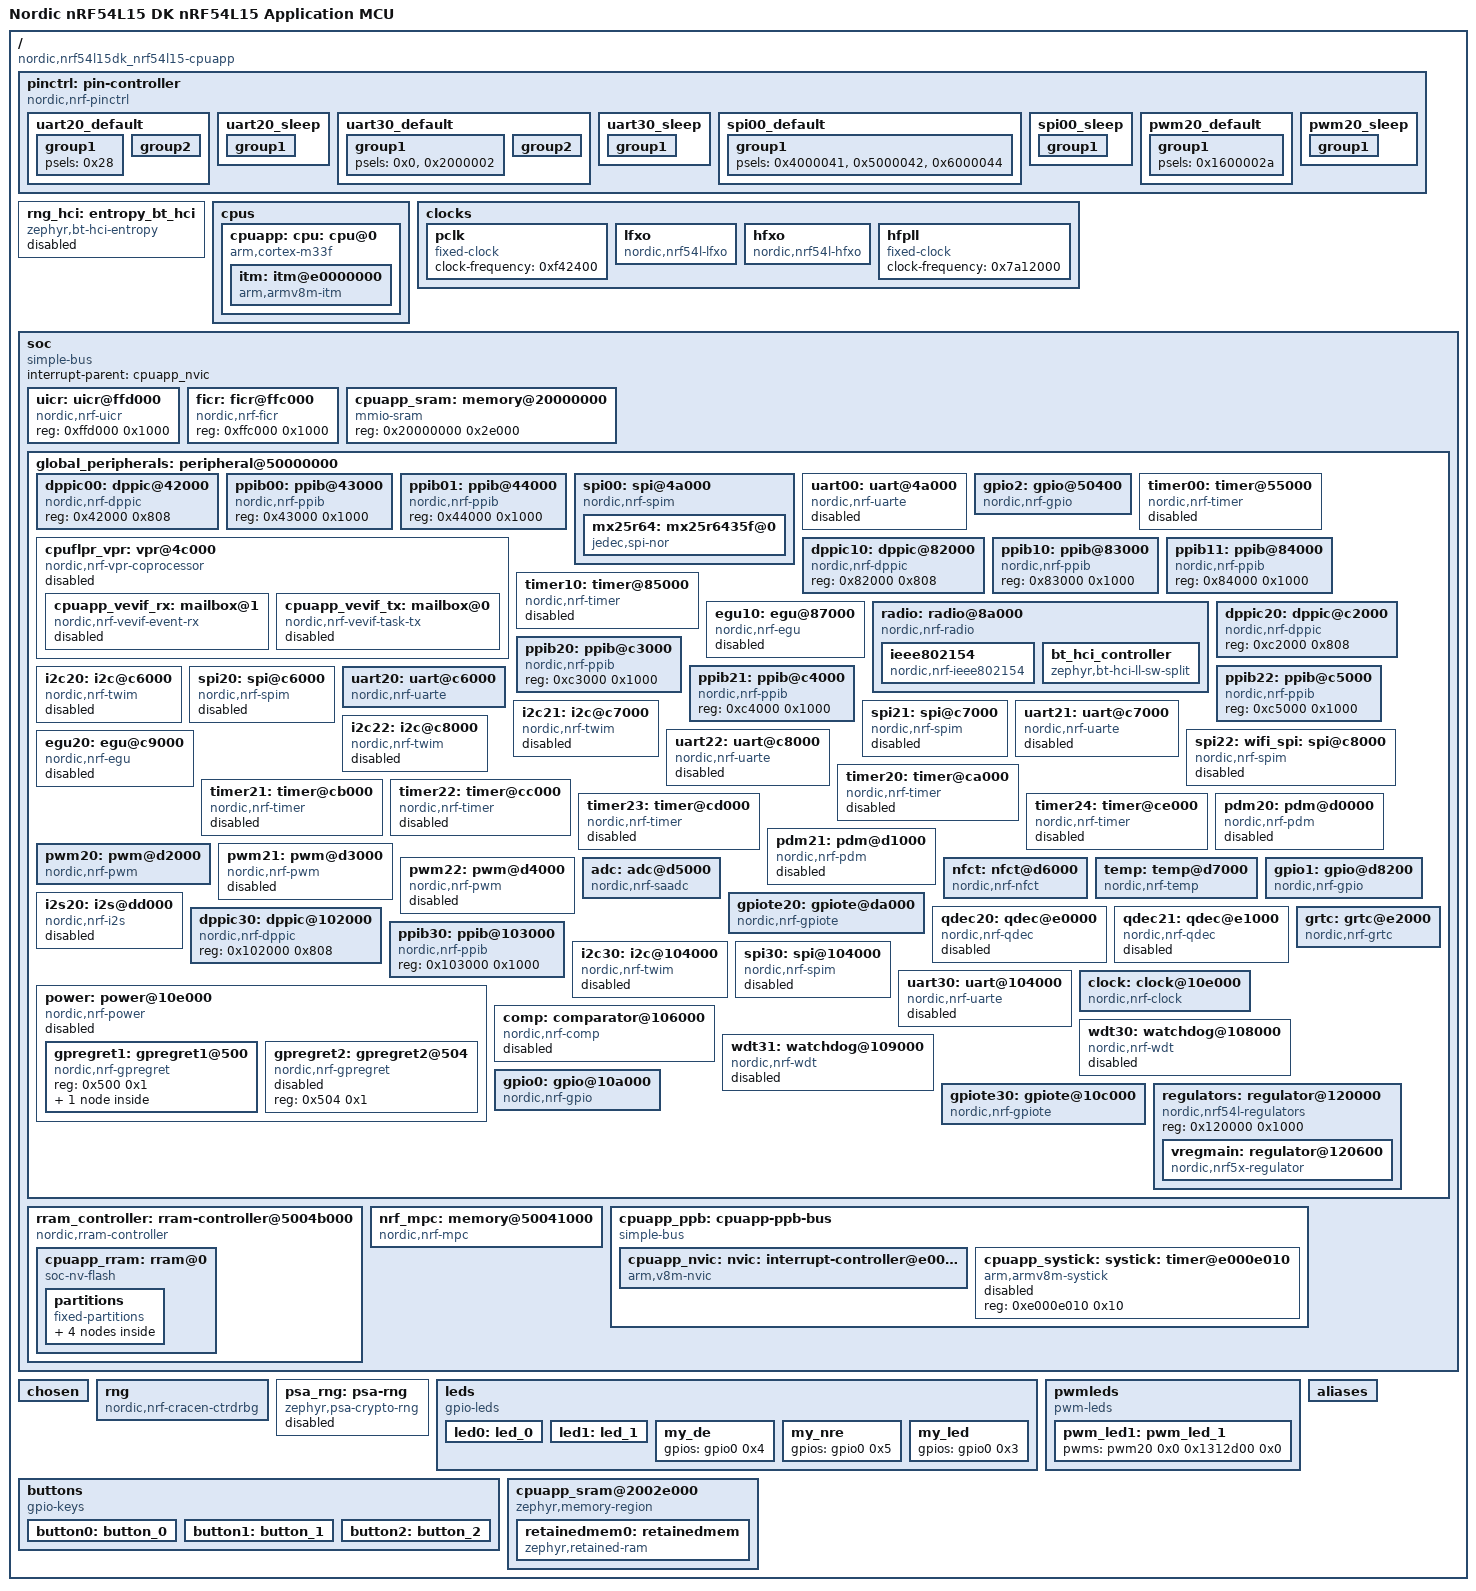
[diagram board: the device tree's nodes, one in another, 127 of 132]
/dts-v1/;

/* node '/' defined in zephyr\dts\vendor\nordic\nrf_common.dtsi:25 */
/ {
	#address-cells = < 0x1 >;                              /* in zephyr\dts\vendor\nordic\nrf54l_05_10_15.dtsi:19 */
	#size-cells = < 0x1 >;                                 /* in zephyr\dts\vendor\nordic\nrf54l_05_10_15.dtsi:20 */
	compatible = "nordic,nrf54l15dk_nrf54l15-cpuapp";      /* in zephyr\boards\nordic\nrf54l15dk\nrf54l15dk_nrf54l15_cpuapp.dts:13 */
	model = "Nordic nRF54L15 DK nRF54L15 Application MCU"; /* in zephyr\boards\nordic\nrf54l15dk\nrf54l15dk_nrf54l15_cpuapp.dts:14 */

	/* node '/pin-controller' defined in zephyr\dts\vendor\nordic\nrf_common.dtsi:26 */
	pinctrl: pin-controller {
		compatible = "nordic,nrf-pinctrl"; /* in zephyr\dts\vendor\nordic\nrf_common.dtsi:31 */

		/* node '/pin-controller/uart20_default' defined in zephyr\boards\nordic\nrf54l15dk\nrf54l15dk_nrf54l_05_10_15-pinctrl.dtsi:7 */
		uart20_default: uart20_default {
			phandle = < 0x8 >; /* in zephyr\boards\nordic\nrf54l15dk\nrf54l15dk_common.dtsi:92 */

			/* node '/pin-controller/uart20_default/group1' defined in zephyr\boards\nordic\nrf54l15dk\nrf54l15dk_nrf54l_05_10_15-pinctrl.dtsi:8 */
			group1 {
				psels = < 0x28 >; /* in zephyr\power_test\boards\nrf54l15dk_nrf54l15_cpuapp.overlay:9 */
			};

			/* node '/pin-controller/uart20_default/group2' defined in zephyr\boards\nordic\nrf54l15dk\nrf54l15dk_nrf54l_05_10_15-pinctrl.dtsi:13 */
			group2 {
				psels = < 0x1000029 >; /* in zephyr\power_test\boards\nrf54l15dk_nrf54l15_cpuapp.overlay:12 */
				bias-pull-up;          /* in zephyr\power_test\boards\nrf54l15dk_nrf54l15_cpuapp.overlay:13 */
			};
		};

		/* node '/pin-controller/uart20_sleep' defined in zephyr\boards\nordic\nrf54l15dk\nrf54l15dk_nrf54l_05_10_15-pinctrl.dtsi:20 */
		uart20_sleep: uart20_sleep {
			phandle = < 0x9 >; /* in zephyr\boards\nordic\nrf54l15dk\nrf54l15dk_common.dtsi:93 */

			/* node '/pin-controller/uart20_sleep/group1' defined in zephyr\boards\nordic\nrf54l15dk\nrf54l15dk_nrf54l_05_10_15-pinctrl.dtsi:21 */
			group1 {
				psels = < 0x28 >,
				        < 0x1000029 >; /* in zephyr\power_test\boards\nrf54l15dk_nrf54l15_cpuapp.overlay:19 */
				low-power-enable;      /* in zephyr\power_test\boards\nrf54l15dk_nrf54l15_cpuapp.overlay:21 */
			};
		};

		/* node '/pin-controller/uart30_default' defined in zephyr\boards\nordic\nrf54l15dk\nrf54l15dk_nrf54l_05_10_15-pinctrl.dtsi:30 */
		uart30_default: uart30_default {
			phandle = < 0xf >; /* in zephyr\boards\nordic\nrf54l15dk\nrf54l15dk_common.dtsi:99 */

			/* node '/pin-controller/uart30_default/group1' defined in zephyr\boards\nordic\nrf54l15dk\nrf54l15dk_nrf54l_05_10_15-pinctrl.dtsi:31 */
			group1 {
				psels = < 0x0 >,
				        < 0x2000002 >; /* in zephyr\power_test\boards\nrf54l15dk_nrf54l15_cpuapp.overlay:27 */
			};

			/* node '/pin-controller/uart30_default/group2' defined in zephyr\boards\nordic\nrf54l15dk\nrf54l15dk_nrf54l_05_10_15-pinctrl.dtsi:36 */
			group2 {
				psels = < 0x1000001 >,
				        < 0x3000003 >; /* in zephyr\power_test\boards\nrf54l15dk_nrf54l15_cpuapp.overlay:31 */
				bias-pull-up;          /* in zephyr\power_test\boards\nrf54l15dk_nrf54l15_cpuapp.overlay:33 */
			};
		};

		/* node '/pin-controller/uart30_sleep' defined in zephyr\boards\nordic\nrf54l15dk\nrf54l15dk_nrf54l_05_10_15-pinctrl.dtsi:43 */
		uart30_sleep: uart30_sleep {
			phandle = < 0x10 >; /* in zephyr\boards\nordic\nrf54l15dk\nrf54l15dk_common.dtsi:100 */

			/* node '/pin-controller/uart30_sleep/group1' defined in zephyr\boards\nordic\nrf54l15dk\nrf54l15dk_nrf54l_05_10_15-pinctrl.dtsi:44 */
			group1 {
				psels = < 0x0 >,
				        < 0x1000001 >,
				        < 0x2000002 >,
				        < 0x3000003 >; /* in zephyr\power_test\boards\nrf54l15dk_nrf54l15_cpuapp.overlay:39 */
				low-power-enable;      /* in zephyr\power_test\boards\nrf54l15dk_nrf54l15_cpuapp.overlay:43 */
			};
		};

		/* node '/pin-controller/spi00_default' defined in zephyr\boards\nordic\nrf54l15dk\nrf54l15dk_nrf54l_05_10_15-pinctrl.dtsi:53 */
		spi00_default: spi00_default {
			phandle = < 0x4 >; /* in zephyr\boards\nordic\nrf54l15dk\nrf54l_05_10_15_cpuapp_common.dtsi:117 */

			/* node '/pin-controller/spi00_default/group1' defined in zephyr\boards\nordic\nrf54l15dk\nrf54l15dk_nrf54l_05_10_15-pinctrl.dtsi:54 */
			group1 {
				psels = < 0x4000041 >,
				        < 0x5000042 >,
				        < 0x6000044 >; /* in zephyr\power_test\boards\nrf54l15dk_nrf54l15_cpuapp.overlay:49 */
			};
		};

		/* node '/pin-controller/spi00_sleep' defined in zephyr\boards\nordic\nrf54l15dk\nrf54l15dk_nrf54l_05_10_15-pinctrl.dtsi:61 */
		spi00_sleep: spi00_sleep {
			phandle = < 0x5 >; /* in zephyr\boards\nordic\nrf54l15dk\nrf54l_05_10_15_cpuapp_common.dtsi:118 */

			/* node '/pin-controller/spi00_sleep/group1' defined in zephyr\boards\nordic\nrf54l15dk\nrf54l15dk_nrf54l_05_10_15-pinctrl.dtsi:62 */
			group1 {
				psels = < 0x4000041 >,
				        < 0x5000042 >,
				        < 0x6000044 >; /* in zephyr\power_test\boards\nrf54l15dk_nrf54l15_cpuapp.overlay:57 */
				low-power-enable;      /* in zephyr\power_test\boards\nrf54l15dk_nrf54l15_cpuapp.overlay:60 */
			};
		};

		/* node '/pin-controller/pwm20_default' defined in zephyr\boards\nordic\nrf54l15dk\nrf54l15dk_nrf54l_05_10_15-pinctrl.dtsi:70 */
		pwm20_default: pwm20_default {
			phandle = < 0xa >; /* in zephyr\boards\nordic\nrf54l15dk\nrf54l15dk_common.dtsi:106 */

			/* node '/pin-controller/pwm20_default/group1' defined in zephyr\boards\nordic\nrf54l15dk\nrf54l15dk_nrf54l_05_10_15-pinctrl.dtsi:71 */
			group1 {
				psels = < 0x1600002a >; /* in zephyr\power_test\boards\nrf54l15dk_nrf54l15_cpuapp.overlay:66 */
			};
		};

		/* node '/pin-controller/pwm20_sleep' defined in zephyr\boards\nordic\nrf54l15dk\nrf54l15dk_nrf54l_05_10_15-pinctrl.dtsi:76 */
		pwm20_sleep: pwm20_sleep {
			phandle = < 0xb >; /* in zephyr\boards\nordic\nrf54l15dk\nrf54l15dk_common.dtsi:107 */

			/* node '/pin-controller/pwm20_sleep/group1' defined in zephyr\boards\nordic\nrf54l15dk\nrf54l15dk_nrf54l_05_10_15-pinctrl.dtsi:77 */
			group1 {
				psels = < 0x1600002a >; /* in zephyr\power_test\boards\nrf54l15dk_nrf54l15_cpuapp.overlay:72 */
				low-power-enable;       /* in zephyr\power_test\boards\nrf54l15dk_nrf54l15_cpuapp.overlay:73 */
			};
		};
	};

	/* node '/entropy_bt_hci' defined in zephyr\dts\vendor\nordic\nrf_common.dtsi:34 */
	rng_hci: entropy_bt_hci {
		compatible = "zephyr,bt-hci-entropy"; /* in zephyr\dts\vendor\nordic\nrf_common.dtsi:35 */
		status = "disabled";                  /* in zephyr\dts\vendor\nordic\nrf_common.dtsi:36 */
	};

	/* node '/cpus' defined in zephyr\dts\vendor\nordic\nrf54l_05_10_15.dtsi:22 */
	cpus {
		#address-cells = < 0x1 >; /* in zephyr\dts\vendor\nordic\nrf54l_05_10_15.dtsi:23 */
		#size-cells = < 0x0 >;    /* in zephyr\dts\vendor\nordic\nrf54l_05_10_15.dtsi:24 */

		/* node '/cpus/cpu@0' defined in zephyr\dts\vendor\nordic\nrf54l_05_10_15.dtsi:26 */
		cpuapp: cpu: cpu@0 {
			compatible = "arm,cortex-m33f"; /* in zephyr\dts\vendor\nordic\nrf54l_05_10_15.dtsi:27 */
			reg = < 0x0 >;                  /* in zephyr\dts\vendor\nordic\nrf54l_05_10_15.dtsi:28 */
			device_type = "cpu";            /* in zephyr\dts\vendor\nordic\nrf54l_05_10_15.dtsi:29 */
			clocks = < &hfpll >;            /* in zephyr\dts\vendor\nordic\nrf54l_05_10_15.dtsi:30 */
			#address-cells = < 0x1 >;       /* in zephyr\dts\vendor\nordic\nrf54l_05_10_15.dtsi:31 */
			#size-cells = < 0x1 >;          /* in zephyr\dts\vendor\nordic\nrf54l_05_10_15.dtsi:32 */

			/* node '/cpus/cpu@0/itm@e0000000' defined in zephyr\dts\vendor\nordic\nrf54l_05_10_15.dtsi:34 */
			itm: itm@e0000000 {
				compatible = "arm,armv8m-itm";     /* in zephyr\dts\vendor\nordic\nrf54l_05_10_15.dtsi:35 */
				reg = < 0xe0000000 0x1000 >;       /* in zephyr\dts\vendor\nordic\nrf54l_05_10_15.dtsi:36 */
				swo-ref-frequency = < 0x7a12000 >; /* in zephyr\dts\vendor\nordic\nrf54l_05_10_15.dtsi:37 */
			};
		};
	};

	/* node '/clocks' defined in zephyr\dts\vendor\nordic\nrf54l_05_10_15.dtsi:51 */
	clocks {

		/* node '/clocks/pclk' defined in zephyr\dts\vendor\nordic\nrf54l_05_10_15.dtsi:52 */
		pclk: pclk {
			compatible = "fixed-clock";     /* in zephyr\dts\vendor\nordic\nrf54l_05_10_15.dtsi:53 */
			#clock-cells = < 0x0 >;         /* in zephyr\dts\vendor\nordic\nrf54l_05_10_15.dtsi:54 */
			clock-frequency = < 0xf42400 >; /* in zephyr\dts\vendor\nordic\nrf54l_05_10_15.dtsi:55 */
			phandle = < 0xe >;              /* in zephyr\dts\vendor\nordic\nrf54l_05_10_15.dtsi:580 */
		};

		/* node '/clocks/lfxo' defined in zephyr\dts\vendor\nordic\nrf54l_05_10_15.dtsi:58 */
		lfxo: lfxo {
			compatible = "nordic,nrf54l-lfxo";        /* in zephyr\dts\vendor\nordic\nrf54l_05_10_15.dtsi:59 */
			#clock-cells = < 0x0 >;                   /* in zephyr\dts\vendor\nordic\nrf54l_05_10_15.dtsi:60 */
			clock-frequency = < 0x8000 >;             /* in zephyr\dts\vendor\nordic\nrf54l_05_10_15.dtsi:61 */
			load-capacitors = "internal";             /* in zephyr\boards\nordic\nrf54l15dk\nrf54l_05_10_15_cpuapp_common.dtsi:35 */
			load-capacitance-femtofarad = < 0x4268 >; /* in zephyr\boards\nordic\nrf54l15dk\nrf54l_05_10_15_cpuapp_common.dtsi:36 */
			phandle = < 0xd >;                        /* in zephyr\dts\vendor\nordic\nrf54l_05_10_15.dtsi:580 */
		};

		/* node '/clocks/hfxo' defined in zephyr\dts\vendor\nordic\nrf54l_05_10_15.dtsi:64 */
		hfxo: hfxo {
			compatible = "nordic,nrf54l-hfxo";        /* in zephyr\dts\vendor\nordic\nrf54l_05_10_15.dtsi:65 */
			#clock-cells = < 0x0 >;                   /* in zephyr\dts\vendor\nordic\nrf54l_05_10_15.dtsi:66 */
			clock-frequency = < 0x1e84800 >;          /* in zephyr\dts\vendor\nordic\nrf54l_05_10_15.dtsi:67 */
			startup-time-us = < 0x672 >;              /* in zephyr\dts\vendor\nordic\nrf54l_05_10_15.dtsi:68 */
			load-capacitors = "internal";             /* in zephyr\boards\nordic\nrf54l15dk\nrf54l_05_10_15_cpuapp_common.dtsi:40 */
			load-capacitance-femtofarad = < 0x3a98 >; /* in zephyr\boards\nordic\nrf54l15dk\nrf54l_05_10_15_cpuapp_common.dtsi:41 */
			phandle = < 0x6 >;                        /* in zephyr\dts\vendor\nordic\nrf54l_05_10_15.dtsi:229 */
		};

		/* node '/clocks/hfpll' defined in zephyr\dts\vendor\nordic\nrf54l_05_10_15.dtsi:71 */
		hfpll: hfpll {
			compatible = "fixed-clock";      /* in zephyr\dts\vendor\nordic\nrf54l_05_10_15.dtsi:72 */
			#clock-cells = < 0x0 >;          /* in zephyr\dts\vendor\nordic\nrf54l_05_10_15.dtsi:73 */
			clock-frequency = < 0x7a12000 >; /* in zephyr\dts\vendor\nordic\nrf54l_05_10_15.dtsi:74 */
			phandle = < 0x1 >;               /* in zephyr\dts\vendor\nordic\nrf54l_05_10_15.dtsi:30 */
		};
	};

	/* node '/soc' defined in zephyr\dts\vendor\nordic\nrf54l_05_10_15.dtsi:78 */
	soc {
		#address-cells = < 0x1 >;            /* in zephyr\dts\vendor\nordic\nrf54l_05_10_15.dtsi:79 */
		#size-cells = < 0x1 >;               /* in zephyr\dts\vendor\nordic\nrf54l_05_10_15.dtsi:80 */
		compatible = "simple-bus";           /* in zephyr\dts\arm\nordic\nrf54l_05_10_15_cpuapp.dtsi:25 */
		interrupt-parent = < &cpuapp_nvic >; /* in zephyr\dts\arm\nordic\nrf54l_05_10_15_cpuapp.dtsi:26 */
		ranges;                              /* in zephyr\dts\arm\nordic\nrf54l_05_10_15_cpuapp.dtsi:27 */

		/* node '/soc/uicr@ffd000' defined in zephyr\dts\vendor\nordic\nrf54l_05_10_15.dtsi:86 */
		uicr: uicr@ffd000 {
			compatible = "nordic,nrf-uicr"; /* in zephyr\dts\vendor\nordic\nrf54l_05_10_15.dtsi:87 */
			reg = < 0xffd000 0x1000 >;      /* in zephyr\dts\vendor\nordic\nrf54l_05_10_15.dtsi:88 */
		};

		/* node '/soc/ficr@ffc000' defined in zephyr\dts\vendor\nordic\nrf54l_05_10_15.dtsi:92 */
		ficr: ficr@ffc000 {
			compatible = "nordic,nrf-ficr"; /* in zephyr\dts\vendor\nordic\nrf54l_05_10_15.dtsi:93 */
			reg = < 0xffc000 0x1000 >;      /* in zephyr\dts\vendor\nordic\nrf54l_05_10_15.dtsi:94 */
			#nordic,ficr-cells = < 0x1 >;   /* in zephyr\dts\vendor\nordic\nrf54l_05_10_15.dtsi:95 */
		};

		/* node '/soc/memory@20000000' defined in zephyr\dts\vendor\nordic\nrf54l_05_10_15.dtsi:98 */
		cpuapp_sram: memory@20000000 {
			compatible = "mmio-sram";            /* in zephyr\dts\vendor\nordic\nrf54l_05_10_15.dtsi:99 */
			#address-cells = < 0x1 >;            /* in zephyr\dts\vendor\nordic\nrf54l_05_10_15.dtsi:100 */
			#size-cells = < 0x1 >;               /* in zephyr\dts\vendor\nordic\nrf54l_05_10_15.dtsi:101 */
			status = "okay";                     /* in zephyr\boards\nordic\nrf54l15dk\nrf54l_05_10_15_cpuapp_common.dtsi:31 */
			reg = < 0x20000000 0x2e000 >;        /* in zephyr\power_test\boards\nrf54l15dk_nrf54l15_cpuapp.overlay:107 */
			ranges = < 0x0 0x20000000 0x2e000 >; /* in zephyr\power_test\boards\nrf54l15dk_nrf54l15_cpuapp.overlay:108 */
		};

		/* node '/soc/peripheral@50000000' defined in zephyr\dts\vendor\nordic\nrf54l_05_10_15.dtsi:111 */
		global_peripherals: peripheral@50000000 {
			#address-cells = < 0x1 >;               /* in zephyr\dts\vendor\nordic\nrf54l_05_10_15.dtsi:112 */
			#size-cells = < 0x1 >;                  /* in zephyr\dts\vendor\nordic\nrf54l_05_10_15.dtsi:113 */
			ranges = < 0x0 0x50000000 0x10000000 >; /* in zephyr\dts\vendor\nordic\nrf54l_05_10_15.dtsi:114 */

			/* node '/soc/peripheral@50000000/dppic@42000' defined in zephyr\dts\vendor\nordic\nrf54l_05_10_15.dtsi:117 */
			dppic00: dppic@42000 {
				compatible = "nordic,nrf-dppic"; /* in zephyr\dts\vendor\nordic\nrf54l_05_10_15.dtsi:118 */
				reg = < 0x42000 0x808 >;         /* in zephyr\dts\vendor\nordic\nrf54l_05_10_15.dtsi:119 */
				status = "okay";                 /* in zephyr\dts\arm\nordic\nrf54l_05_10_15_cpuapp.dtsi:97 */
			};

			/* node '/soc/peripheral@50000000/ppib@43000' defined in zephyr\dts\vendor\nordic\nrf54l_05_10_15.dtsi:123 */
			ppib00: ppib@43000 {
				compatible = "nordic,nrf-ppib"; /* in zephyr\dts\vendor\nordic\nrf54l_05_10_15.dtsi:124 */
				reg = < 0x43000 0x1000 >;       /* in zephyr\dts\vendor\nordic\nrf54l_05_10_15.dtsi:125 */
				status = "okay";                /* in zephyr\dts\arm\nordic\nrf54l_05_10_15_cpuapp.dtsi:113 */
			};

			/* node '/soc/peripheral@50000000/ppib@44000' defined in zephyr\dts\vendor\nordic\nrf54l_05_10_15.dtsi:129 */
			ppib01: ppib@44000 {
				compatible = "nordic,nrf-ppib"; /* in zephyr\dts\vendor\nordic\nrf54l_05_10_15.dtsi:130 */
				reg = < 0x44000 0x1000 >;       /* in zephyr\dts\vendor\nordic\nrf54l_05_10_15.dtsi:131 */
				status = "okay";                /* in zephyr\dts\arm\nordic\nrf54l_05_10_15_cpuapp.dtsi:117 */
			};

			/* node '/soc/peripheral@50000000/spi@4a000' defined in zephyr\dts\vendor\nordic\nrf54l_05_10_15.dtsi:135 */
			spi00: spi@4a000 {
				compatible = "nordic,nrf-spim"; /* in zephyr\dts\vendor\nordic\nrf54l_05_10_15.dtsi:142 */
				#address-cells = < 0x1 >;       /* in zephyr\dts\vendor\nordic\nrf54l_05_10_15.dtsi:143 */
				#size-cells = < 0x0 >;          /* in zephyr\dts\vendor\nordic\nrf54l_05_10_15.dtsi:144 */
				reg = < 0x4a000 0x1000 >;       /* in zephyr\dts\vendor\nordic\nrf54l_05_10_15.dtsi:145 */
				interrupts = < 0x4a 0x1 >;      /* in zephyr\dts\vendor\nordic\nrf54l_05_10_15.dtsi:146 */
				max-frequency = < 0x1e84800 >;  /* in zephyr\dts\vendor\nordic\nrf54l_05_10_15.dtsi:147 */
				easydma-maxcnt-bits = < 0x10 >; /* in zephyr\dts\vendor\nordic\nrf54l_05_10_15.dtsi:148 */
				rx-delay-supported;             /* in zephyr\dts\vendor\nordic\nrf54l_05_10_15.dtsi:149 */
				rx-delay = < 0x1 >;             /* in zephyr\dts\vendor\nordic\nrf54l_05_10_15.dtsi:150 */
				status = "okay";                /* in zephyr\boards\nordic\nrf54l15dk\nrf54l_05_10_15_cpuapp_common.dtsi:115 */
				cs-gpios = < &gpio2 0x5 0x1 >;  /* in zephyr\boards\nordic\nrf54l15dk\nrf54l_05_10_15_cpuapp_common.dtsi:116 */
				pinctrl-0 = < &spi00_default >; /* in zephyr\boards\nordic\nrf54l15dk\nrf54l_05_10_15_cpuapp_common.dtsi:117 */
				pinctrl-1 = < &spi00_sleep >;   /* in zephyr\boards\nordic\nrf54l15dk\nrf54l_05_10_15_cpuapp_common.dtsi:118 */
				pinctrl-names = "default",
				                "sleep";        /* in zephyr\boards\nordic\nrf54l15dk\nrf54l_05_10_15_cpuapp_common.dtsi:119 */

				/* node '/soc/peripheral@50000000/spi@4a000/mx25r6435f@0' defined in zephyr\boards\nordic\nrf54l15dk\nrf54l_05_10_15_cpuapp_common.dtsi:121 */
				mx25r64: mx25r6435f@0 {
					compatible = "jedec,spi-nor";                                                                 /* in zephyr\boards\nordic\nrf54l15dk\nrf54l_05_10_15_cpuapp_common.dtsi:122 */
					status = "okay";                                                                              /* in zephyr\boards\nordic\nrf54l15dk\nrf54l_05_10_15_cpuapp_common.dtsi:123 */
					reg = < 0x0 >;                                                                                /* in zephyr\boards\nordic\nrf54l15dk\nrf54l_05_10_15_cpuapp_common.dtsi:124 */
					spi-max-frequency = < 0x7a1200 >;                                                             /* in zephyr\boards\nordic\nrf54l15dk\nrf54l_05_10_15_cpuapp_common.dtsi:125 */
					jedec-id = [ C2 28 17 ];                                                                      /* in zephyr\boards\nordic\nrf54l15dk\nrf54l_05_10_15_cpuapp_common.dtsi:126 */
					sfdp-bfp = [ E5 20 F1 FF FF FF FF 03 44 EB 08 6B 08 3B 04 BB EE FF FF FF FF FF 00 FF FF FF 00
					             FF 0C 20 0F 52 10 D8 00 FF 23 72 F5 00 82 ED 04 CC 44 83 48 44 30 B0 30 B0 F7 C4
					             D5 5C 00 BE 29 FF F0 D0 FF FF ];                                                 /* in zephyr\boards\nordic\nrf54l15dk\nrf54l_05_10_15_cpuapp_common.dtsi:127 */
					size = < 0x4000000 >;                                                                         /* in zephyr\boards\nordic\nrf54l15dk\nrf54l_05_10_15_cpuapp_common.dtsi:131 */
					has-dpd;                                                                                      /* in zephyr\boards\nordic\nrf54l15dk\nrf54l_05_10_15_cpuapp_common.dtsi:132 */
					t-enter-dpd = < 0x2710 >;                                                                     /* in zephyr\boards\nordic\nrf54l15dk\nrf54l_05_10_15_cpuapp_common.dtsi:133 */
					t-exit-dpd = < 0x88b8 >;                                                                      /* in zephyr\boards\nordic\nrf54l15dk\nrf54l_05_10_15_cpuapp_common.dtsi:134 */
					reset-gpios = < &gpio2 0x0 0x1 >;                                                             /* in zephyr\boards\nordic\nrf54l15dk\nrf54l_05_10_15_cpuapp_common.dtsi:135 */
				};
			};

			/* node '/soc/peripheral@50000000/uart@4a000' defined in zephyr\dts\vendor\nordic\nrf54l_05_10_15.dtsi:154 */
			uart00: uart@4a000 {
				compatible = "nordic,nrf-uarte"; /* in zephyr\dts\vendor\nordic\nrf54l_05_10_15.dtsi:155 */
				reg = < 0x4a000 0x1000 >;        /* in zephyr\dts\vendor\nordic\nrf54l_05_10_15.dtsi:156 */
				interrupts = < 0x4a 0x1 >;       /* in zephyr\dts\vendor\nordic\nrf54l_05_10_15.dtsi:157 */
				clocks = < &hfpll >;             /* in zephyr\dts\vendor\nordic\nrf54l_05_10_15.dtsi:158 */
				status = "disabled";             /* in zephyr\dts\vendor\nordic\nrf54l_05_10_15.dtsi:159 */
				endtx-stoptx-supported;          /* in zephyr\dts\vendor\nordic\nrf54l_05_10_15.dtsi:160 */
				frame-timeout-supported;         /* in zephyr\dts\vendor\nordic\nrf54l_05_10_15.dtsi:161 */
			};

			/* node '/soc/peripheral@50000000/vpr@4c000' defined in zephyr\dts\vendor\nordic\nrf54l_05_10_15.dtsi:164 */
			cpuflpr_vpr: vpr@4c000 {
				compatible = "nordic,nrf-vpr-coprocessor"; /* in zephyr\dts\vendor\nordic\nrf54l_05_10_15.dtsi:165 */
				reg = < 0x4c000 0x1000 >;                  /* in zephyr\dts\vendor\nordic\nrf54l_05_10_15.dtsi:166 */
				ranges = < 0x0 0x4c000 0x1000 >;           /* in zephyr\dts\vendor\nordic\nrf54l_05_10_15.dtsi:167 */
				#address-cells = < 0x1 >;                  /* in zephyr\dts\vendor\nordic\nrf54l_05_10_15.dtsi:168 */
				#size-cells = < 0x1 >;                     /* in zephyr\dts\vendor\nordic\nrf54l_05_10_15.dtsi:169 */
				status = "disabled";                       /* in zephyr\dts\vendor\nordic\nrf54l_05_10_15.dtsi:170 */
				enable-secure;                             /* in zephyr\dts\vendor\nordic\nrf54l_05_10_15.dtsi:171 */

				/* node '/soc/peripheral@50000000/vpr@4c000/mailbox@1' defined in zephyr\dts\arm\nordic\nrf54l_05_10_15_cpuapp.dtsi:46 */
				cpuapp_vevif_rx: mailbox@1 {
					compatible = "nordic,nrf-vevif-event-rx"; /* in zephyr\dts\arm\nordic\nrf54l_05_10_15_cpuapp.dtsi:47 */
					reg = < 0x1 0x1000 >;                     /* in zephyr\dts\arm\nordic\nrf54l_05_10_15_cpuapp.dtsi:48 */
					status = "disabled";                      /* in zephyr\dts\arm\nordic\nrf54l_05_10_15_cpuapp.dtsi:49 */
					interrupts = < 0x4c 0x1 >;                /* in zephyr\dts\arm\nordic\nrf54l_05_10_15_cpuapp.dtsi:50 */
					#mbox-cells = < 0x1 >;                    /* in zephyr\dts\arm\nordic\nrf54l_05_10_15_cpuapp.dtsi:51 */
					nordic,events = < 0x1 >;                  /* in zephyr\dts\arm\nordic\nrf54l_05_10_15_cpuapp.dtsi:52 */
					nordic,events-mask = < 0x100000 >;        /* in zephyr\dts\arm\nordic\nrf54l_05_10_15_cpuapp.dtsi:53 */
				};

				/* node '/soc/peripheral@50000000/vpr@4c000/mailbox@0' defined in zephyr\dts\arm\nordic\nrf54l_05_10_15_cpuapp.dtsi:56 */
				cpuapp_vevif_tx: mailbox@0 {
					compatible = "nordic,nrf-vevif-task-tx"; /* in zephyr\dts\arm\nordic\nrf54l_05_10_15_cpuapp.dtsi:57 */
					reg = < 0x0 0x1000 >;                    /* in zephyr\dts\arm\nordic\nrf54l_05_10_15_cpuapp.dtsi:58 */
					#mbox-cells = < 0x1 >;                   /* in zephyr\dts\arm\nordic\nrf54l_05_10_15_cpuapp.dtsi:59 */
					nordic,tasks = < 0x7 >;                  /* in zephyr\dts\arm\nordic\nrf54l_05_10_15_cpuapp.dtsi:60 */
					nordic,tasks-mask = < 0x7f0000 >;        /* in zephyr\dts\arm\nordic\nrf54l_05_10_15_cpuapp.dtsi:61 */
					status = "disabled";                     /* in zephyr\dts\arm\nordic\nrf54l_05_10_15_cpuapp.dtsi:62 */
				};
			};

			/* node '/soc/peripheral@50000000/gpio@50400' defined in zephyr\dts\vendor\nordic\nrf54l_05_10_15.dtsi:183 */
			gpio2: gpio@50400 {
				compatible = "nordic,nrf-gpio"; /* in zephyr\dts\vendor\nordic\nrf54l_05_10_15.dtsi:184 */
				gpio-controller;                /* in zephyr\dts\vendor\nordic\nrf54l_05_10_15.dtsi:185 */
				reg = < 0x50400 0x300 >;        /* in zephyr\dts\vendor\nordic\nrf54l_05_10_15.dtsi:186 */
				#gpio-cells = < 0x2 >;          /* in zephyr\dts\vendor\nordic\nrf54l_05_10_15.dtsi:187 */
				ngpios = < 0xb >;               /* in zephyr\dts\vendor\nordic\nrf54l_05_10_15.dtsi:188 */
				port = < 0x2 >;                 /* in zephyr\dts\vendor\nordic\nrf54l_05_10_15.dtsi:190 */
				status = "okay";                /* in zephyr\boards\nordic\nrf54l15dk\nrf54l_05_10_15_cpuapp_common.dtsi:77 */
				phandle = < 0x3 >;              /* in zephyr\boards\nordic\nrf54l15dk\nrf54l_05_10_15_cpuapp_common.dtsi:116 */
			};

			/* node '/soc/peripheral@50000000/timer@55000' defined in zephyr\dts\vendor\nordic\nrf54l_05_10_15.dtsi:193 */
			timer00: timer@55000 {
				compatible = "nordic,nrf-timer"; /* in zephyr\dts\vendor\nordic\nrf54l_05_10_15.dtsi:194 */
				status = "disabled";             /* in zephyr\dts\vendor\nordic\nrf54l_05_10_15.dtsi:195 */
				reg = < 0x55000 0x1000 >;        /* in zephyr\dts\vendor\nordic\nrf54l_05_10_15.dtsi:196 */
				cc-num = < 0x6 >;                /* in zephyr\dts\vendor\nordic\nrf54l_05_10_15.dtsi:197 */
				max-bit-width = < 0x20 >;        /* in zephyr\dts\vendor\nordic\nrf54l_05_10_15.dtsi:198 */
				interrupts = < 0x55 0x1 >;       /* in zephyr\dts\vendor\nordic\nrf54l_05_10_15.dtsi:199 */
				clocks = < &hfpll >;             /* in zephyr\dts\vendor\nordic\nrf54l_05_10_15.dtsi:200 */
				prescaler = < 0x0 >;             /* in zephyr\dts\vendor\nordic\nrf54l_05_10_15.dtsi:201 */
			};

			/* node '/soc/peripheral@50000000/dppic@82000' defined in zephyr\dts\vendor\nordic\nrf54l_05_10_15.dtsi:204 */
			dppic10: dppic@82000 {
				compatible = "nordic,nrf-dppic"; /* in zephyr\dts\vendor\nordic\nrf54l_05_10_15.dtsi:205 */
				reg = < 0x82000 0x808 >;         /* in zephyr\dts\vendor\nordic\nrf54l_05_10_15.dtsi:206 */
				status = "okay";                 /* in zephyr\dts\arm\nordic\nrf54l_05_10_15_cpuapp.dtsi:101 */
			};

			/* node '/soc/peripheral@50000000/ppib@83000' defined in zephyr\dts\vendor\nordic\nrf54l_05_10_15.dtsi:210 */
			ppib10: ppib@83000 {
				compatible = "nordic,nrf-ppib"; /* in zephyr\dts\vendor\nordic\nrf54l_05_10_15.dtsi:211 */
				reg = < 0x83000 0x1000 >;       /* in zephyr\dts\vendor\nordic\nrf54l_05_10_15.dtsi:212 */
				status = "okay";                /* in zephyr\dts\arm\nordic\nrf54l_05_10_15_cpuapp.dtsi:121 */
			};

			/* node '/soc/peripheral@50000000/ppib@84000' defined in zephyr\dts\vendor\nordic\nrf54l_05_10_15.dtsi:216 */
			ppib11: ppib@84000 {
				compatible = "nordic,nrf-ppib"; /* in zephyr\dts\vendor\nordic\nrf54l_05_10_15.dtsi:217 */
				reg = < 0x84000 0x1000 >;       /* in zephyr\dts\vendor\nordic\nrf54l_05_10_15.dtsi:218 */
				status = "okay";                /* in zephyr\dts\arm\nordic\nrf54l_05_10_15_cpuapp.dtsi:125 */
			};

			/* node '/soc/peripheral@50000000/timer@85000' defined in zephyr\dts\vendor\nordic\nrf54l_05_10_15.dtsi:222 */
			timer10: timer@85000 {
				compatible = "nordic,nrf-timer"; /* in zephyr\dts\vendor\nordic\nrf54l_05_10_15.dtsi:223 */
				status = "disabled";             /* in zephyr\dts\vendor\nordic\nrf54l_05_10_15.dtsi:224 */
				reg = < 0x85000 0x1000 >;        /* in zephyr\dts\vendor\nordic\nrf54l_05_10_15.dtsi:225 */
				cc-num = < 0x8 >;                /* in zephyr\dts\vendor\nordic\nrf54l_05_10_15.dtsi:226 */
				max-bit-width = < 0x20 >;        /* in zephyr\dts\vendor\nordic\nrf54l_05_10_15.dtsi:227 */
				interrupts = < 0x85 0x1 >;       /* in zephyr\dts\vendor\nordic\nrf54l_05_10_15.dtsi:228 */
				clocks = < &hfxo >;              /* in zephyr\dts\vendor\nordic\nrf54l_05_10_15.dtsi:229 */
				prescaler = < 0x0 >;             /* in zephyr\dts\vendor\nordic\nrf54l_05_10_15.dtsi:230 */
			};

			/* node '/soc/peripheral@50000000/egu@87000' defined in zephyr\dts\vendor\nordic\nrf54l_05_10_15.dtsi:233 */
			egu10: egu@87000 {
				compatible = "nordic,nrf-egu"; /* in zephyr\dts\vendor\nordic\nrf54l_05_10_15.dtsi:234 */
				reg = < 0x87000 0x1000 >;      /* in zephyr\dts\vendor\nordic\nrf54l_05_10_15.dtsi:235 */
				interrupts = < 0x87 0x1 >;     /* in zephyr\dts\vendor\nordic\nrf54l_05_10_15.dtsi:236 */
				status = "disabled";           /* in zephyr\dts\vendor\nordic\nrf54l_05_10_15.dtsi:237 */
			};

			/* node '/soc/peripheral@50000000/radio@8a000' defined in zephyr\dts\vendor\nordic\nrf54l_05_10_15.dtsi:240 */
			radio: radio@8a000 {
				compatible = "nordic,nrf-radio"; /* in zephyr\dts\vendor\nordic\nrf54l_05_10_15.dtsi:241 */
				reg = < 0x8a000 0x1000 >;        /* in zephyr\dts\vendor\nordic\nrf54l_05_10_15.dtsi:242 */
				interrupts = < 0x8a 0x1 >;       /* in zephyr\dts\vendor\nordic\nrf54l_05_10_15.dtsi:243 */
				dfe-supported;                   /* in zephyr\dts\vendor\nordic\nrf54l_05_10_15.dtsi:245 */
				ieee802154-supported;            /* in zephyr\dts\vendor\nordic\nrf54l_05_10_15.dtsi:246 */
				ble-2mbps-supported;             /* in zephyr\dts\vendor\nordic\nrf54l_05_10_15.dtsi:247 */
				ble-coded-phy-supported;         /* in zephyr\dts\vendor\nordic\nrf54l_05_10_15.dtsi:248 */
				cs-supported;                    /* in zephyr\dts\vendor\nordic\nrf54l_05_10_15.dtsi:249 */
				status = "okay";                 /* in zephyr\boards\nordic\nrf54l15dk\nrf54l_05_10_15_cpuapp_common.dtsi:89 */

				/* node '/soc/peripheral@50000000/radio@8a000/ieee802154' defined in zephyr\dts\vendor\nordic\nrf54l_05_10_15.dtsi:251 */
				ieee802154: ieee802154 {
					compatible = "nordic,nrf-ieee802154"; /* in zephyr\dts\vendor\nordic\nrf54l_05_10_15.dtsi:252 */
					status = "okay";                      /* in zephyr\power_test\boards\nrf54l15dk_nrf54l15_cpuapp.overlay:160 */
				};

				/* node '/soc/peripheral@50000000/radio@8a000/bt_hci_controller' defined in zephyr\dts\vendor\nordic\nrf54l_05_10_15.dtsi:259 */
				bt_hci_controller: bt_hci_controller {
					compatible = "zephyr,bt-hci-ll-sw-split"; /* in zephyr\dts\vendor\nordic\nrf54l_05_10_15.dtsi:260 */
					status = "okay";                          /* in zephyr\dts\arm\nordic\nrf54l_05_10_15_cpuapp.dtsi:42 */
				};
			};

			/* node '/soc/peripheral@50000000/dppic@c2000' defined in zephyr\dts\vendor\nordic\nrf54l_05_10_15.dtsi:265 */
			dppic20: dppic@c2000 {
				compatible = "nordic,nrf-dppic"; /* in zephyr\dts\vendor\nordic\nrf54l_05_10_15.dtsi:266 */
				reg = < 0xc2000 0x808 >;         /* in zephyr\dts\vendor\nordic\nrf54l_05_10_15.dtsi:267 */
				status = "okay";                 /* in zephyr\dts\arm\nordic\nrf54l_05_10_15_cpuapp.dtsi:105 */
			};

			/* node '/soc/peripheral@50000000/ppib@c3000' defined in zephyr\dts\vendor\nordic\nrf54l_05_10_15.dtsi:271 */
			ppib20: ppib@c3000 {
				compatible = "nordic,nrf-ppib"; /* in zephyr\dts\vendor\nordic\nrf54l_05_10_15.dtsi:272 */
				reg = < 0xc3000 0x1000 >;       /* in zephyr\dts\vendor\nordic\nrf54l_05_10_15.dtsi:273 */
				status = "okay";                /* in zephyr\dts\arm\nordic\nrf54l_05_10_15_cpuapp.dtsi:129 */
			};

			/* node '/soc/peripheral@50000000/ppib@c4000' defined in zephyr\dts\vendor\nordic\nrf54l_05_10_15.dtsi:277 */
			ppib21: ppib@c4000 {
				compatible = "nordic,nrf-ppib"; /* in zephyr\dts\vendor\nordic\nrf54l_05_10_15.dtsi:278 */
				reg = < 0xc4000 0x1000 >;       /* in zephyr\dts\vendor\nordic\nrf54l_05_10_15.dtsi:279 */
				status = "okay";                /* in zephyr\dts\arm\nordic\nrf54l_05_10_15_cpuapp.dtsi:133 */
			};

			/* node '/soc/peripheral@50000000/ppib@c5000' defined in zephyr\dts\vendor\nordic\nrf54l_05_10_15.dtsi:283 */
			ppib22: ppib@c5000 {
				compatible = "nordic,nrf-ppib"; /* in zephyr\dts\vendor\nordic\nrf54l_05_10_15.dtsi:284 */
				reg = < 0xc5000 0x1000 >;       /* in zephyr\dts\vendor\nordic\nrf54l_05_10_15.dtsi:285 */
				status = "okay";                /* in zephyr\dts\arm\nordic\nrf54l_05_10_15_cpuapp.dtsi:137 */
			};

			/* node '/soc/peripheral@50000000/i2c@c6000' defined in zephyr\dts\vendor\nordic\nrf54l_05_10_15.dtsi:289 */
			i2c20: i2c@c6000 {
				compatible = "nordic,nrf-twim"; /* in zephyr\dts\vendor\nordic\nrf54l_05_10_15.dtsi:290 */
				#address-cells = < 0x1 >;       /* in zephyr\dts\vendor\nordic\nrf54l_05_10_15.dtsi:291 */
				#size-cells = < 0x0 >;          /* in zephyr\dts\vendor\nordic\nrf54l_05_10_15.dtsi:292 */
				reg = < 0xc6000 0x1000 >;       /* in zephyr\dts\vendor\nordic\nrf54l_05_10_15.dtsi:293 */
				interrupts = < 0xc6 0x1 >;      /* in zephyr\dts\vendor\nordic\nrf54l_05_10_15.dtsi:294 */
				easydma-maxcnt-bits = < 0x10 >; /* in zephyr\dts\vendor\nordic\nrf54l_05_10_15.dtsi:295 */
				status = "disabled";            /* in zephyr\dts\vendor\nordic\nrf54l_05_10_15.dtsi:296 */
				zephyr,pm-device-runtime-auto;  /* in zephyr\dts\vendor\nordic\nrf54l_05_10_15.dtsi:297 */
			};

			/* node '/soc/peripheral@50000000/spi@c6000' defined in zephyr\dts\vendor\nordic\nrf54l_05_10_15.dtsi:300 */
			spi20: spi@c6000 {
				compatible = "nordic,nrf-spim"; /* in zephyr\dts\vendor\nordic\nrf54l_05_10_15.dtsi:307 */
				#address-cells = < 0x1 >;       /* in zephyr\dts\vendor\nordic\nrf54l_05_10_15.dtsi:308 */
				#size-cells = < 0x0 >;          /* in zephyr\dts\vendor\nordic\nrf54l_05_10_15.dtsi:309 */
				reg = < 0xc6000 0x1000 >;       /* in zephyr\dts\vendor\nordic\nrf54l_05_10_15.dtsi:310 */
				interrupts = < 0xc6 0x1 >;      /* in zephyr\dts\vendor\nordic\nrf54l_05_10_15.dtsi:311 */
				max-frequency = < 0x7a1200 >;   /* in zephyr\dts\vendor\nordic\nrf54l_05_10_15.dtsi:312 */
				easydma-maxcnt-bits = < 0x10 >; /* in zephyr\dts\vendor\nordic\nrf54l_05_10_15.dtsi:313 */
				rx-delay-supported;             /* in zephyr\dts\vendor\nordic\nrf54l_05_10_15.dtsi:314 */
				rx-delay = < 0x1 >;             /* in zephyr\dts\vendor\nordic\nrf54l_05_10_15.dtsi:315 */
				status = "disabled";            /* in zephyr\dts\vendor\nordic\nrf54l_05_10_15.dtsi:316 */
				default-gpio-port = < &gpio1 >; /* in zephyr\dts\vendor\nordic\nrf54l_05_10_15.dtsi:317 */
				cross-domain-pins-supported;    /* in zephyr\dts\vendor\nordic\nrf54l_05_10_15.dtsi:318 */
			};

			/* node '/soc/peripheral@50000000/uart@c6000' defined in zephyr\dts\vendor\nordic\nrf54l_05_10_15.dtsi:321 */
			uart20: uart@c6000 {
				compatible = "nordic,nrf-uarte"; /* in zephyr\dts\vendor\nordic\nrf54l_05_10_15.dtsi:322 */
				reg = < 0xc6000 0x1000 >;        /* in zephyr\dts\vendor\nordic\nrf54l_05_10_15.dtsi:323 */
				interrupts = < 0xc6 0x1 >;       /* in zephyr\dts\vendor\nordic\nrf54l_05_10_15.dtsi:324 */
				endtx-stoptx-supported;          /* in zephyr\dts\vendor\nordic\nrf54l_05_10_15.dtsi:326 */
				frame-timeout-supported;         /* in zephyr\dts\vendor\nordic\nrf54l_05_10_15.dtsi:327 */
				default-gpio-port = < &gpio1 >;  /* in zephyr\dts\vendor\nordic\nrf54l_05_10_15.dtsi:328 */
				cross-domain-pins-supported;     /* in zephyr\dts\vendor\nordic\nrf54l_05_10_15.dtsi:329 */
				current-speed = < 0x1c200 >;     /* in zephyr\boards\nordic\nrf54l15dk\nrf54l15dk_common.dtsi:91 */
				pinctrl-0 = < &uart20_default >; /* in zephyr\boards\nordic\nrf54l15dk\nrf54l15dk_common.dtsi:92 */
				pinctrl-1 = < &uart20_sleep >;   /* in zephyr\boards\nordic\nrf54l15dk\nrf54l15dk_common.dtsi:93 */
				pinctrl-names = "default",
				                "sleep";         /* in zephyr\boards\nordic\nrf54l15dk\nrf54l15dk_common.dtsi:94 */
				status = "okay";                 /* in zephyr\power_test\boards\nrf54l15dk_nrf54l15_cpuapp.overlay:137 */
			};

			/* node '/soc/peripheral@50000000/i2c@c7000' defined in zephyr\dts\vendor\nordic\nrf54l_05_10_15.dtsi:332 */
			i2c21: i2c@c7000 {
				compatible = "nordic,nrf-twim"; /* in zephyr\dts\vendor\nordic\nrf54l_05_10_15.dtsi:333 */
				#address-cells = < 0x1 >;       /* in zephyr\dts\vendor\nordic\nrf54l_05_10_15.dtsi:334 */
				#size-cells = < 0x0 >;          /* in zephyr\dts\vendor\nordic\nrf54l_05_10_15.dtsi:335 */
				reg = < 0xc7000 0x1000 >;       /* in zephyr\dts\vendor\nordic\nrf54l_05_10_15.dtsi:336 */
				interrupts = < 0xc7 0x1 >;      /* in zephyr\dts\vendor\nordic\nrf54l_05_10_15.dtsi:337 */
				easydma-maxcnt-bits = < 0x10 >; /* in zephyr\dts\vendor\nordic\nrf54l_05_10_15.dtsi:338 */
				status = "disabled";            /* in zephyr\dts\vendor\nordic\nrf54l_05_10_15.dtsi:339 */
				zephyr,pm-device-runtime-auto;  /* in zephyr\dts\vendor\nordic\nrf54l_05_10_15.dtsi:340 */
			};

			/* node '/soc/peripheral@50000000/spi@c7000' defined in zephyr\dts\vendor\nordic\nrf54l_05_10_15.dtsi:343 */
			spi21: spi@c7000 {
				compatible = "nordic,nrf-spim"; /* in zephyr\dts\vendor\nordic\nrf54l_05_10_15.dtsi:350 */
				#address-cells = < 0x1 >;       /* in zephyr\dts\vendor\nordic\nrf54l_05_10_15.dtsi:351 */
				#size-cells = < 0x0 >;          /* in zephyr\dts\vendor\nordic\nrf54l_05_10_15.dtsi:352 */
				reg = < 0xc7000 0x1000 >;       /* in zephyr\dts\vendor\nordic\nrf54l_05_10_15.dtsi:353 */
				interrupts = < 0xc7 0x1 >;      /* in zephyr\dts\vendor\nordic\nrf54l_05_10_15.dtsi:354 */
				max-frequency = < 0x7a1200 >;   /* in zephyr\dts\vendor\nordic\nrf54l_05_10_15.dtsi:355 */
				easydma-maxcnt-bits = < 0x10 >; /* in zephyr\dts\vendor\nordic\nrf54l_05_10_15.dtsi:356 */
				rx-delay-supported;             /* in zephyr\dts\vendor\nordic\nrf54l_05_10_15.dtsi:357 */
				rx-delay = < 0x1 >;             /* in zephyr\dts\vendor\nordic\nrf54l_05_10_15.dtsi:358 */
				status = "disabled";            /* in zephyr\dts\vendor\nordic\nrf54l_05_10_15.dtsi:359 */
				default-gpio-port = < &gpio1 >; /* in zephyr\dts\vendor\nordic\nrf54l_05_10_15.dtsi:360 */
				cross-domain-pins-supported;    /* in zephyr\dts\vendor\nordic\nrf54l_05_10_15.dtsi:361 */
			};

			/* node '/soc/peripheral@50000000/uart@c7000' defined in zephyr\dts\vendor\nordic\nrf54l_05_10_15.dtsi:364 */
			uart21: uart@c7000 {
				compatible = "nordic,nrf-uarte"; /* in zephyr\dts\vendor\nordic\nrf54l_05_10_15.dtsi:365 */
				reg = < 0xc7000 0x1000 >;        /* in zephyr\dts\vendor\nordic\nrf54l_05_10_15.dtsi:366 */
				interrupts = < 0xc7 0x1 >;       /* in zephyr\dts\vendor\nordic\nrf54l_05_10_15.dtsi:367 */
				status = "disabled";             /* in zephyr\dts\vendor\nordic\nrf54l_05_10_15.dtsi:368 */
				endtx-stoptx-supported;          /* in zephyr\dts\vendor\nordic\nrf54l_05_10_15.dtsi:369 */
				frame-timeout-supported;         /* in zephyr\dts\vendor\nordic\nrf54l_05_10_15.dtsi:370 */
				default-gpio-port = < &gpio1 >;  /* in zephyr\dts\vendor\nordic\nrf54l_05_10_15.dtsi:371 */
				cross-domain-pins-supported;     /* in zephyr\dts\vendor\nordic\nrf54l_05_10_15.dtsi:372 */
			};

			/* node '/soc/peripheral@50000000/i2c@c8000' defined in zephyr\dts\vendor\nordic\nrf54l_05_10_15.dtsi:375 */
			i2c22: i2c@c8000 {
				compatible = "nordic,nrf-twim"; /* in zephyr\dts\vendor\nordic\nrf54l_05_10_15.dtsi:376 */
				#address-cells = < 0x1 >;       /* in zephyr\dts\vendor\nordic\nrf54l_05_10_15.dtsi:377 */
				#size-cells = < 0x0 >;          /* in zephyr\dts\vendor\nordic\nrf54l_05_10_15.dtsi:378 */
				reg = < 0xc8000 0x1000 >;       /* in zephyr\dts\vendor\nordic\nrf54l_05_10_15.dtsi:379 */
				interrupts = < 0xc8 0x1 >;      /* in zephyr\dts\vendor\nordic\nrf54l_05_10_15.dtsi:380 */
				easydma-maxcnt-bits = < 0x10 >; /* in zephyr\dts\vendor\nordic\nrf54l_05_10_15.dtsi:381 */
				status = "disabled";            /* in zephyr\dts\vendor\nordic\nrf54l_05_10_15.dtsi:382 */
				zephyr,pm-device-runtime-auto;  /* in zephyr\dts\vendor\nordic\nrf54l_05_10_15.dtsi:383 */
			};

			/* node '/soc/peripheral@50000000/spi@c8000' defined in zephyr\dts\vendor\nordic\nrf54l_05_10_15.dtsi:386 */
			spi22: wifi_spi: spi@c8000 {
				compatible = "nordic,nrf-spim"; /* in zephyr\dts\vendor\nordic\nrf54l_05_10_15.dtsi:393 */
				#address-cells = < 0x1 >;       /* in zephyr\dts\vendor\nordic\nrf54l_05_10_15.dtsi:394 */
				#size-cells = < 0x0 >;          /* in zephyr\dts\vendor\nordic\nrf54l_05_10_15.dtsi:395 */
				reg = < 0xc8000 0x1000 >;       /* in zephyr\dts\vendor\nordic\nrf54l_05_10_15.dtsi:396 */
				interrupts = < 0xc8 0x1 >;      /* in zephyr\dts\vendor\nordic\nrf54l_05_10_15.dtsi:397 */
				max-frequency = < 0x7a1200 >;   /* in zephyr\dts\vendor\nordic\nrf54l_05_10_15.dtsi:398 */
				easydma-maxcnt-bits = < 0x10 >; /* in zephyr\dts\vendor\nordic\nrf54l_05_10_15.dtsi:399 */
				rx-delay-supported;             /* in zephyr\dts\vendor\nordic\nrf54l_05_10_15.dtsi:400 */
				rx-delay = < 0x1 >;             /* in zephyr\dts\vendor\nordic\nrf54l_05_10_15.dtsi:401 */
				status = "disabled";            /* in zephyr\dts\vendor\nordic\nrf54l_05_10_15.dtsi:402 */
			};

			/* node '/soc/peripheral@50000000/uart@c8000' defined in zephyr\dts\vendor\nordic\nrf54l_05_10_15.dtsi:405 */
			uart22: uart@c8000 {
				compatible = "nordic,nrf-uarte"; /* in zephyr\dts\vendor\nordic\nrf54l_05_10_15.dtsi:406 */
				reg = < 0xc8000 0x1000 >;        /* in zephyr\dts\vendor\nordic\nrf54l_05_10_15.dtsi:407 */
				interrupts = < 0xc8 0x1 >;       /* in zephyr\dts\vendor\nordic\nrf54l_05_10_15.dtsi:408 */
				status = "disabled";             /* in zephyr\dts\vendor\nordic\nrf54l_05_10_15.dtsi:409 */
				endtx-stoptx-supported;          /* in zephyr\dts\vendor\nordic\nrf54l_05_10_15.dtsi:410 */
				frame-timeout-supported;         /* in zephyr\dts\vendor\nordic\nrf54l_05_10_15.dtsi:411 */
			};

			/* node '/soc/peripheral@50000000/egu@c9000' defined in zephyr\dts\vendor\nordic\nrf54l_05_10_15.dtsi:414 */
			egu20: egu@c9000 {
				compatible = "nordic,nrf-egu"; /* in zephyr\dts\vendor\nordic\nrf54l_05_10_15.dtsi:415 */
				reg = < 0xc9000 0x1000 >;      /* in zephyr\dts\vendor\nordic\nrf54l_05_10_15.dtsi:416 */
				interrupts = < 0xc9 0x1 >;     /* in zephyr\dts\vendor\nordic\nrf54l_05_10_15.dtsi:417 */
				status = "disabled";           /* in zephyr\dts\vendor\nordic\nrf54l_05_10_15.dtsi:418 */
			};

			/* node '/soc/peripheral@50000000/timer@ca000' defined in zephyr\dts\vendor\nordic\nrf54l_05_10_15.dtsi:421 */
			timer20: timer@ca000 {
				compatible = "nordic,nrf-timer"; /* in zephyr\dts\vendor\nordic\nrf54l_05_10_15.dtsi:422 */
				status = "disabled";             /* in zephyr\dts\vendor\nordic\nrf54l_05_10_15.dtsi:423 */
				reg = < 0xca000 0x1000 >;        /* in zephyr\dts\vendor\nordic\nrf54l_05_10_15.dtsi:424 */
				cc-num = < 0x6 >;                /* in zephyr\dts\vendor\nordic\nrf54l_05_10_15.dtsi:425 */
				max-bit-width = < 0x20 >;        /* in zephyr\dts\vendor\nordic\nrf54l_05_10_15.dtsi:426 */
				interrupts = < 0xca 0x1 >;       /* in zephyr\dts\vendor\nordic\nrf54l_05_10_15.dtsi:427 */
				prescaler = < 0x0 >;             /* in zephyr\dts\vendor\nordic\nrf54l_05_10_15.dtsi:428 */
			};

			/* node '/soc/peripheral@50000000/timer@cb000' defined in zephyr\dts\vendor\nordic\nrf54l_05_10_15.dtsi:431 */
			timer21: timer@cb000 {
				compatible = "nordic,nrf-timer"; /* in zephyr\dts\vendor\nordic\nrf54l_05_10_15.dtsi:432 */
				status = "disabled";             /* in zephyr\dts\vendor\nordic\nrf54l_05_10_15.dtsi:433 */
				reg = < 0xcb000 0x1000 >;        /* in zephyr\dts\vendor\nordic\nrf54l_05_10_15.dtsi:434 */
				cc-num = < 0x6 >;                /* in zephyr\dts\vendor\nordic\nrf54l_05_10_15.dtsi:435 */
				max-bit-width = < 0x20 >;        /* in zephyr\dts\vendor\nordic\nrf54l_05_10_15.dtsi:436 */
				interrupts = < 0xcb 0x1 >;       /* in zephyr\dts\vendor\nordic\nrf54l_05_10_15.dtsi:437 */
				prescaler = < 0x0 >;             /* in zephyr\dts\vendor\nordic\nrf54l_05_10_15.dtsi:438 */
			};

			/* node '/soc/peripheral@50000000/timer@cc000' defined in zephyr\dts\vendor\nordic\nrf54l_05_10_15.dtsi:441 */
			timer22: timer@cc000 {
				compatible = "nordic,nrf-timer"; /* in zephyr\dts\vendor\nordic\nrf54l_05_10_15.dtsi:442 */
				status = "disabled";             /* in zephyr\dts\vendor\nordic\nrf54l_05_10_15.dtsi:443 */
				reg = < 0xcc000 0x1000 >;        /* in zephyr\dts\vendor\nordic\nrf54l_05_10_15.dtsi:444 */
				cc-num = < 0x6 >;                /* in zephyr\dts\vendor\nordic\nrf54l_05_10_15.dtsi:445 */
				max-bit-width = < 0x20 >;        /* in zephyr\dts\vendor\nordic\nrf54l_05_10_15.dtsi:446 */
				interrupts = < 0xcc 0x1 >;       /* in zephyr\dts\vendor\nordic\nrf54l_05_10_15.dtsi:447 */
				prescaler = < 0x0 >;             /* in zephyr\dts\vendor\nordic\nrf54l_05_10_15.dtsi:448 */
			};

			/* node '/soc/peripheral@50000000/timer@cd000' defined in zephyr\dts\vendor\nordic\nrf54l_05_10_15.dtsi:451 */
			timer23: timer@cd000 {
				compatible = "nordic,nrf-timer"; /* in zephyr\dts\vendor\nordic\nrf54l_05_10_15.dtsi:452 */
				status = "disabled";             /* in zephyr\dts\vendor\nordic\nrf54l_05_10_15.dtsi:453 */
				reg = < 0xcd000 0x1000 >;        /* in zephyr\dts\vendor\nordic\nrf54l_05_10_15.dtsi:454 */
				cc-num = < 0x6 >;                /* in zephyr\dts\vendor\nordic\nrf54l_05_10_15.dtsi:455 */
				max-bit-width = < 0x20 >;        /* in zephyr\dts\vendor\nordic\nrf54l_05_10_15.dtsi:456 */
				interrupts = < 0xcd 0x1 >;       /* in zephyr\dts\vendor\nordic\nrf54l_05_10_15.dtsi:457 */
				prescaler = < 0x0 >;             /* in zephyr\dts\vendor\nordic\nrf54l_05_10_15.dtsi:458 */
			};

			/* node '/soc/peripheral@50000000/timer@ce000' defined in zephyr\dts\vendor\nordic\nrf54l_05_10_15.dtsi:461 */
			timer24: timer@ce000 {
				compatible = "nordic,nrf-timer"; /* in zephyr\dts\vendor\nordic\nrf54l_05_10_15.dtsi:462 */
				status = "disabled";             /* in zephyr\dts\vendor\nordic\nrf54l_05_10_15.dtsi:463 */
				reg = < 0xce000 0x1000 >;        /* in zephyr\dts\vendor\nordic\nrf54l_05_10_15.dtsi:464 */
				cc-num = < 0x6 >;                /* in zephyr\dts\vendor\nordic\nrf54l_05_10_15.dtsi:465 */
				max-bit-width = < 0x20 >;        /* in zephyr\dts\vendor\nordic\nrf54l_05_10_15.dtsi:466 */
				interrupts = < 0xce 0x1 >;       /* in zephyr\dts\vendor\nordic\nrf54l_05_10_15.dtsi:467 */
				prescaler = < 0x0 >;             /* in zephyr\dts\vendor\nordic\nrf54l_05_10_15.dtsi:468 */
			};

			/* node '/soc/peripheral@50000000/pdm@d0000' defined in zephyr\dts\vendor\nordic\nrf54l_05_10_15.dtsi:471 */
			pdm20: pdm@d0000 {
				compatible = "nordic,nrf-pdm"; /* in zephyr\dts\vendor\nordic\nrf54l_05_10_15.dtsi:472 */
				status = "disabled";           /* in zephyr\dts\vendor\nordic\nrf54l_05_10_15.dtsi:473 */
				reg = < 0xd0000 0x1000 >;      /* in zephyr\dts\vendor\nordic\nrf54l_05_10_15.dtsi:474 */
				interrupts = < 0xd0 0x1 >;     /* in zephyr\dts\vendor\nordic\nrf54l_05_10_15.dtsi:475 */
			};

			/* node '/soc/peripheral@50000000/pdm@d1000' defined in zephyr\dts\vendor\nordic\nrf54l_05_10_15.dtsi:478 */
			pdm21: pdm@d1000 {
				compatible = "nordic,nrf-pdm"; /* in zephyr\dts\vendor\nordic\nrf54l_05_10_15.dtsi:479 */
				status = "disabled";           /* in zephyr\dts\vendor\nordic\nrf54l_05_10_15.dtsi:480 */
				reg = < 0xd1000 0x1000 >;      /* in zephyr\dts\vendor\nordic\nrf54l_05_10_15.dtsi:481 */
				interrupts = < 0xd1 0x1 >;     /* in zephyr\dts\vendor\nordic\nrf54l_05_10_15.dtsi:482 */
			};

			/* node '/soc/peripheral@50000000/pwm@d2000' defined in zephyr\dts\vendor\nordic\nrf54l_05_10_15.dtsi:485 */
			pwm20: pwm@d2000 {
				compatible = "nordic,nrf-pwm";  /* in zephyr\dts\vendor\nordic\nrf54l_05_10_15.dtsi:486 */
				reg = < 0xd2000 0x1000 >;       /* in zephyr\dts\vendor\nordic\nrf54l_05_10_15.dtsi:488 */
				interrupts = < 0xd2 0x1 >;      /* in zephyr\dts\vendor\nordic\nrf54l_05_10_15.dtsi:489 */
				#pwm-cells = < 0x3 >;           /* in zephyr\dts\vendor\nordic\nrf54l_05_10_15.dtsi:490 */
				idleout-supported;              /* in zephyr\dts\vendor\nordic\nrf54l_05_10_15.dtsi:491 */
				status = "okay";                /* in zephyr\boards\nordic\nrf54l15dk\nrf54l15dk_common.dtsi:105 */
				pinctrl-0 = < &pwm20_default >; /* in zephyr\boards\nordic\nrf54l15dk\nrf54l15dk_common.dtsi:106 */
				pinctrl-1 = < &pwm20_sleep >;   /* in zephyr\boards\nordic\nrf54l15dk\nrf54l15dk_common.dtsi:107 */
				pinctrl-names = "default",
				                "sleep";        /* in zephyr\boards\nordic\nrf54l15dk\nrf54l15dk_common.dtsi:108 */
				phandle = < 0x13 >;             /* in zephyr\boards\nordic\nrf54l15dk\nrf54l15dk_common.dtsi:44 */
			};

			/* node '/soc/peripheral@50000000/pwm@d3000' defined in zephyr\dts\vendor\nordic\nrf54l_05_10_15.dtsi:494 */
			pwm21: pwm@d3000 {
				compatible = "nordic,nrf-pwm"; /* in zephyr\dts\vendor\nordic\nrf54l_05_10_15.dtsi:495 */
				status = "disabled";           /* in zephyr\dts\vendor\nordic\nrf54l_05_10_15.dtsi:496 */
				reg = < 0xd3000 0x1000 >;      /* in zephyr\dts\vendor\nordic\nrf54l_05_10_15.dtsi:497 */
				interrupts = < 0xd3 0x1 >;     /* in zephyr\dts\vendor\nordic\nrf54l_05_10_15.dtsi:498 */
				#pwm-cells = < 0x3 >;          /* in zephyr\dts\vendor\nordic\nrf54l_05_10_15.dtsi:499 */
				idleout-supported;             /* in zephyr\dts\vendor\nordic\nrf54l_05_10_15.dtsi:500 */
			};

			/* node '/soc/peripheral@50000000/pwm@d4000' defined in zephyr\dts\vendor\nordic\nrf54l_05_10_15.dtsi:503 */
			pwm22: pwm@d4000 {
				compatible = "nordic,nrf-pwm"; /* in zephyr\dts\vendor\nordic\nrf54l_05_10_15.dtsi:504 */
				status = "disabled";           /* in zephyr\dts\vendor\nordic\nrf54l_05_10_15.dtsi:505 */
				reg = < 0xd4000 0x1000 >;      /* in zephyr\dts\vendor\nordic\nrf54l_05_10_15.dtsi:506 */
				interrupts = < 0xd4 0x1 >;     /* in zephyr\dts\vendor\nordic\nrf54l_05_10_15.dtsi:507 */
				#pwm-cells = < 0x3 >;          /* in zephyr\dts\vendor\nordic\nrf54l_05_10_15.dtsi:508 */
				idleout-supported;             /* in zephyr\dts\vendor\nordic\nrf54l_05_10_15.dtsi:509 */
			};

			/* node '/soc/peripheral@50000000/adc@d5000' defined in zephyr\dts\vendor\nordic\nrf54l_05_10_15.dtsi:512 */
			adc: adc@d5000 {
				compatible = "nordic,nrf-saadc"; /* in zephyr\dts\vendor\nordic\nrf54l_05_10_15.dtsi:513 */
				reg = < 0xd5000 0x1000 >;        /* in zephyr\dts\vendor\nordic\nrf54l_05_10_15.dtsi:514 */
				interrupts = < 0xd5 0x1 >;       /* in zephyr\dts\vendor\nordic\nrf54l_05_10_15.dtsi:515 */
				#io-channel-cells = < 0x1 >;     /* in zephyr\dts\vendor\nordic\nrf54l_05_10_15.dtsi:517 */
				zephyr,pm-device-runtime-auto;   /* in zephyr\dts\vendor\nordic\nrf54l_05_10_15.dtsi:518 */
				status = "okay";                 /* in zephyr\boards\nordic\nrf54l15dk\nrf54l_05_10_15_cpuapp_common.dtsi:140 */
			};

			/* node '/soc/peripheral@50000000/nfct@d6000' defined in zephyr\dts\vendor\nordic\nrf54l_05_10_15.dtsi:521 */
			nfct: nfct@d6000 {
				compatible = "nordic,nrf-nfct"; /* in zephyr\dts\vendor\nordic\nrf54l_05_10_15.dtsi:522 */
				reg = < 0xd6000 0x1000 >;       /* in zephyr\dts\vendor\nordic\nrf54l_05_10_15.dtsi:523 */
				interrupts = < 0xd6 0x1 >;      /* in zephyr\dts\vendor\nordic\nrf54l_05_10_15.dtsi:524 */
				status = "okay";                /* in zephyr\boards\nordic\nrf54l15dk\nrf54l_05_10_15_cpuapp_common.dtsi:65 */
			};

			/* node '/soc/peripheral@50000000/temp@d7000' defined in zephyr\dts\vendor\nordic\nrf54l_05_10_15.dtsi:528 */
			temp: temp@d7000 {
				compatible = "nordic,nrf-temp"; /* in zephyr\dts\vendor\nordic\nrf54l_05_10_15.dtsi:529 */
				reg = < 0xd7000 0x1000 >;       /* in zephyr\dts\vendor\nordic\nrf54l_05_10_15.dtsi:530 */
				interrupts = < 0xd7 0x1 >;      /* in zephyr\dts\vendor\nordic\nrf54l_05_10_15.dtsi:531 */
				status = "okay";                /* in zephyr\power_test\boards\nrf54l15dk_nrf54l15_cpuapp.overlay:156 */
			};

			/* node '/soc/peripheral@50000000/gpio@d8200' defined in zephyr\dts\vendor\nordic\nrf54l_05_10_15.dtsi:535 */
			gpio1: gpio@d8200 {
				compatible = "nordic,nrf-gpio";  /* in zephyr\dts\vendor\nordic\nrf54l_05_10_15.dtsi:536 */
				gpio-controller;                 /* in zephyr\dts\vendor\nordic\nrf54l_05_10_15.dtsi:537 */
				reg = < 0xd8200 0x300 >;         /* in zephyr\dts\vendor\nordic\nrf54l_05_10_15.dtsi:538 */
				#gpio-cells = < 0x2 >;           /* in zephyr\dts\vendor\nordic\nrf54l_05_10_15.dtsi:539 */
				ngpios = < 0x10 >;               /* in zephyr\dts\vendor\nordic\nrf54l_05_10_15.dtsi:540 */
				port = < 0x1 >;                  /* in zephyr\dts\vendor\nordic\nrf54l_05_10_15.dtsi:542 */
				gpiote-instance = < &gpiote20 >; /* in zephyr\dts\vendor\nordic\nrf54l_05_10_15.dtsi:543 */
				status = "okay";                 /* in zephyr\boards\nordic\nrf54l15dk\nrf54l_05_10_15_cpuapp_common.dtsi:73 */
				phandle = < 0x7 >;               /* in zephyr\dts\vendor\nordic\nrf54l_05_10_15.dtsi:317 */
			};

			/* node '/soc/peripheral@50000000/gpiote@da000' defined in zephyr\dts\vendor\nordic\nrf54l_05_10_15.dtsi:546 */
			gpiote20: gpiote@da000 {
				compatible = "nordic,nrf-gpiote"; /* in zephyr\dts\vendor\nordic\nrf54l_05_10_15.dtsi:547 */
				reg = < 0xda000 0x1000 >;         /* in zephyr\dts\vendor\nordic\nrf54l_05_10_15.dtsi:548 */
				instance = < 0x14 >;              /* in zephyr\dts\vendor\nordic\nrf54l_05_10_15.dtsi:550 */
				interrupts = < 0xdb 0x1 >;        /* in zephyr\dts\arm\nordic\nrf54l_05_10_15_cpuapp.dtsi:84 */
				status = "okay";                  /* in zephyr\boards\nordic\nrf54l15dk\nrf54l_05_10_15_cpuapp_common.dtsi:81 */
				phandle = < 0xc >;                /* in zephyr\dts\vendor\nordic\nrf54l_05_10_15.dtsi:543 */
			};

			/* node '/soc/peripheral@50000000/i2s@dd000' defined in zephyr\dts\vendor\nordic\nrf54l_05_10_15.dtsi:553 */
			i2s20: i2s@dd000 {
				compatible = "nordic,nrf-i2s"; /* in zephyr\dts\vendor\nordic\nrf54l_05_10_15.dtsi:554 */
				#address-cells = < 0x1 >;      /* in zephyr\dts\vendor\nordic\nrf54l_05_10_15.dtsi:555 */
				#size-cells = < 0x0 >;         /* in zephyr\dts\vendor\nordic\nrf54l_05_10_15.dtsi:556 */
				reg = < 0xdd000 0x1000 >;      /* in zephyr\dts\vendor\nordic\nrf54l_05_10_15.dtsi:557 */
				interrupts = < 0xdd 0x1 >;     /* in zephyr\dts\vendor\nordic\nrf54l_05_10_15.dtsi:558 */
				status = "disabled";           /* in zephyr\dts\vendor\nordic\nrf54l_05_10_15.dtsi:559 */
			};

			/* node '/soc/peripheral@50000000/qdec@e0000' defined in zephyr\dts\vendor\nordic\nrf54l_05_10_15.dtsi:562 */
			qdec20: qdec@e0000 {
				compatible = "nordic,nrf-qdec"; /* in zephyr\dts\vendor\nordic\nrf54l_05_10_15.dtsi:563 */
				reg = < 0xe0000 0x1000 >;       /* in zephyr\dts\vendor\nordic\nrf54l_05_10_15.dtsi:564 */
				interrupts = < 0xe0 0x1 >;      /* in zephyr\dts\vendor\nordic\nrf54l_05_10_15.dtsi:565 */
				status = "disabled";            /* in zephyr\dts\vendor\nordic\nrf54l_05_10_15.dtsi:566 */
			};

			/* node '/soc/peripheral@50000000/qdec@e1000' defined in zephyr\dts\vendor\nordic\nrf54l_05_10_15.dtsi:569 */
			qdec21: qdec@e1000 {
				compatible = "nordic,nrf-qdec"; /* in zephyr\dts\vendor\nordic\nrf54l_05_10_15.dtsi:570 */
				reg = < 0xe1000 0x1000 >;       /* in zephyr\dts\vendor\nordic\nrf54l_05_10_15.dtsi:571 */
				interrupts = < 0xe1 0x1 >;      /* in zephyr\dts\vendor\nordic\nrf54l_05_10_15.dtsi:572 */
				status = "disabled";            /* in zephyr\dts\vendor\nordic\nrf54l_05_10_15.dtsi:573 */
			};

			/* node '/soc/peripheral@50000000/grtc@e2000' defined in zephyr\dts\vendor\nordic\nrf54l_05_10_15.dtsi:576 */
			grtc: grtc@e2000 {
				compatible = "nordic,nrf-grtc";                                       /* in zephyr\dts\vendor\nordic\nrf54l_05_10_15.dtsi:577 */
				reg = < 0xe2000 0x1000 >;                                             /* in zephyr\dts\vendor\nordic\nrf54l_05_10_15.dtsi:578 */
				cc-num = < 0xc >;                                                     /* in zephyr\dts\vendor\nordic\nrf54l_05_10_15.dtsi:579 */
				clocks = < &lfxo >,
				         < &pclk >;                                                   /* in zephyr\dts\vendor\nordic\nrf54l_05_10_15.dtsi:580 */
				clock-names = "lfclock",
				              "hfclock";                                              /* in zephyr\dts\vendor\nordic\nrf54l_05_10_15.dtsi:581 */
				interrupts = < 0xe4 0x1 >,
				             < 0xe5 0x1 >;                                            /* in zephyr\dts\arm\nordic\nrf54l_05_10_15_cpuapp.dtsi:75 */
				owned-channels = < 0x0 0x1 0x2 0x3 0x4 0x5 0x6 0x7 0x8 0x9 0xa 0xb >; /* in zephyr\boards\nordic\nrf54l15dk\nrf54l_05_10_15_cpuapp_common.dtsi:54 */
				child-owned-channels = < 0x3 0x4 0x7 0x8 0x9 0xa 0xb >;               /* in zephyr\boards\nordic\nrf54l15dk\nrf54l_05_10_15_cpuapp_common.dtsi:56 */
				status = "okay";                                                      /* in zephyr\boards\nordic\nrf54l15dk\nrf54l_05_10_15_cpuapp_common.dtsi:57 */
			};

			/* node '/soc/peripheral@50000000/dppic@102000' defined in zephyr\dts\vendor\nordic\nrf54l_05_10_15.dtsi:585 */
			dppic30: dppic@102000 {
				compatible = "nordic,nrf-dppic"; /* in zephyr\dts\vendor\nordic\nrf54l_05_10_15.dtsi:586 */
				reg = < 0x102000 0x808 >;        /* in zephyr\dts\vendor\nordic\nrf54l_05_10_15.dtsi:587 */
				status = "okay";                 /* in zephyr\dts\arm\nordic\nrf54l_05_10_15_cpuapp.dtsi:109 */
			};

			/* node '/soc/peripheral@50000000/ppib@103000' defined in zephyr\dts\vendor\nordic\nrf54l_05_10_15.dtsi:591 */
			ppib30: ppib@103000 {
				compatible = "nordic,nrf-ppib"; /* in zephyr\dts\vendor\nordic\nrf54l_05_10_15.dtsi:592 */
				reg = < 0x103000 0x1000 >;      /* in zephyr\dts\vendor\nordic\nrf54l_05_10_15.dtsi:593 */
				status = "okay";                /* in zephyr\dts\arm\nordic\nrf54l_05_10_15_cpuapp.dtsi:141 */
			};

			/* node '/soc/peripheral@50000000/i2c@104000' defined in zephyr\dts\vendor\nordic\nrf54l_05_10_15.dtsi:597 */
			i2c30: i2c@104000 {
				compatible = "nordic,nrf-twim"; /* in zephyr\dts\vendor\nordic\nrf54l_05_10_15.dtsi:598 */
				#address-cells = < 0x1 >;       /* in zephyr\dts\vendor\nordic\nrf54l_05_10_15.dtsi:599 */
				#size-cells = < 0x0 >;          /* in zephyr\dts\vendor\nordic\nrf54l_05_10_15.dtsi:600 */
				reg = < 0x104000 0x1000 >;      /* in zephyr\dts\vendor\nordic\nrf54l_05_10_15.dtsi:601 */
				interrupts = < 0x104 0x1 >;     /* in zephyr\dts\vendor\nordic\nrf54l_05_10_15.dtsi:602 */
				easydma-maxcnt-bits = < 0x10 >; /* in zephyr\dts\vendor\nordic\nrf54l_05_10_15.dtsi:603 */
				status = "disabled";            /* in zephyr\dts\vendor\nordic\nrf54l_05_10_15.dtsi:604 */
				zephyr,pm-device-runtime-auto;  /* in zephyr\dts\vendor\nordic\nrf54l_05_10_15.dtsi:605 */
			};

			/* node '/soc/peripheral@50000000/spi@104000' defined in zephyr\dts\vendor\nordic\nrf54l_05_10_15.dtsi:608 */
			spi30: spi@104000 {
				compatible = "nordic,nrf-spim"; /* in zephyr\dts\vendor\nordic\nrf54l_05_10_15.dtsi:615 */
				#address-cells = < 0x1 >;       /* in zephyr\dts\vendor\nordic\nrf54l_05_10_15.dtsi:616 */
				#size-cells = < 0x0 >;          /* in zephyr\dts\vendor\nordic\nrf54l_05_10_15.dtsi:617 */
				reg = < 0x104000 0x1000 >;      /* in zephyr\dts\vendor\nordic\nrf54l_05_10_15.dtsi:618 */
				interrupts = < 0x104 0x1 >;     /* in zephyr\dts\vendor\nordic\nrf54l_05_10_15.dtsi:619 */
				max-frequency = < 0x7a1200 >;   /* in zephyr\dts\vendor\nordic\nrf54l_05_10_15.dtsi:620 */
				easydma-maxcnt-bits = < 0x10 >; /* in zephyr\dts\vendor\nordic\nrf54l_05_10_15.dtsi:621 */
				rx-delay-supported;             /* in zephyr\dts\vendor\nordic\nrf54l_05_10_15.dtsi:622 */
				rx-delay = < 0x1 >;             /* in zephyr\dts\vendor\nordic\nrf54l_05_10_15.dtsi:623 */
				status = "disabled";            /* in zephyr\dts\vendor\nordic\nrf54l_05_10_15.dtsi:624 */
			};

			/* node '/soc/peripheral@50000000/uart@104000' defined in zephyr\dts\vendor\nordic\nrf54l_05_10_15.dtsi:627 */
			uart30: uart@104000 {
				compatible = "nordic,nrf-uarte"; /* in zephyr\dts\vendor\nordic\nrf54l_05_10_15.dtsi:628 */
				reg = < 0x104000 0x1000 >;       /* in zephyr\dts\vendor\nordic\nrf54l_05_10_15.dtsi:629 */
				interrupts = < 0x104 0x1 >;      /* in zephyr\dts\vendor\nordic\nrf54l_05_10_15.dtsi:630 */
				status = "disabled";             /* in zephyr\dts\vendor\nordic\nrf54l_05_10_15.dtsi:631 */
				endtx-stoptx-supported;          /* in zephyr\dts\vendor\nordic\nrf54l_05_10_15.dtsi:632 */
				frame-timeout-supported;         /* in zephyr\dts\vendor\nordic\nrf54l_05_10_15.dtsi:633 */
				current-speed = < 0x1c200 >;     /* in zephyr\boards\nordic\nrf54l15dk\nrf54l15dk_common.dtsi:98 */
				pinctrl-0 = < &uart30_default >; /* in zephyr\boards\nordic\nrf54l15dk\nrf54l15dk_common.dtsi:99 */
				pinctrl-1 = < &uart30_sleep >;   /* in zephyr\boards\nordic\nrf54l15dk\nrf54l15dk_common.dtsi:100 */
				pinctrl-names = "default",
				                "sleep";         /* in zephyr\boards\nordic\nrf54l15dk\nrf54l15dk_common.dtsi:101 */
			};

			/* node '/soc/peripheral@50000000/clock@10e000' defined in zephyr\dts\vendor\nordic\nrf54l_05_10_15.dtsi:636 */
			clock: clock@10e000 {
				compatible = "nordic,nrf-clock"; /* in zephyr\dts\vendor\nordic\nrf54l_05_10_15.dtsi:637 */
				reg = < 0x10e000 0x1000 >;       /* in zephyr\dts\vendor\nordic\nrf54l_05_10_15.dtsi:638 */
				interrupts = < 0x105 0x1 >;      /* in zephyr\dts\vendor\nordic\nrf54l_05_10_15.dtsi:639 */
				status = "okay";                 /* in zephyr\boards\nordic\nrf54l15dk\nrf54l_05_10_15_cpuapp_common.dtsi:101 */
			};

			/* node '/soc/peripheral@50000000/power@10e000' defined in zephyr\dts\vendor\nordic\nrf54l_05_10_15.dtsi:643 */
			power: power@10e000 {
				compatible = "nordic,nrf-power";  /* in zephyr\dts\vendor\nordic\nrf54l_05_10_15.dtsi:644 */
				reg = < 0x10e000 0x1000 >;        /* in zephyr\dts\vendor\nordic\nrf54l_05_10_15.dtsi:645 */
				ranges = < 0x0 0x10e000 0x1000 >; /* in zephyr\dts\vendor\nordic\nrf54l_05_10_15.dtsi:646 */
				interrupts = < 0x105 0x1 >;       /* in zephyr\dts\vendor\nordic\nrf54l_05_10_15.dtsi:647 */
				status = "disabled";              /* in zephyr\dts\vendor\nordic\nrf54l_05_10_15.dtsi:648 */
				#address-cells = < 0x1 >;         /* in zephyr\dts\vendor\nordic\nrf54l_05_10_15.dtsi:649 */
				#size-cells = < 0x1 >;            /* in zephyr\dts\vendor\nordic\nrf54l_05_10_15.dtsi:650 */

				/* node '/soc/peripheral@50000000/power@10e000/gpregret1@500' defined in zephyr\dts\vendor\nordic\nrf54l_05_10_15.dtsi:652 */
				gpregret1: gpregret1@500 {
					#address-cells = < 0x1 >;           /* in zephyr\dts\vendor\nordic\nrf54l_05_10_15.dtsi:653 */
					#size-cells = < 0x1 >;              /* in zephyr\dts\vendor\nordic\nrf54l_05_10_15.dtsi:654 */
					compatible = "nordic,nrf-gpregret"; /* in zephyr\dts\vendor\nordic\nrf54l_05_10_15.dtsi:655 */
					reg = < 0x500 0x1 >;                /* in zephyr\dts\vendor\nordic\nrf54l_05_10_15.dtsi:656 */
					status = "okay";                    /* in zephyr\boards\nordic\nrf54l15dk\nrf54l_05_10_15_cpuapp_common.dtsi:105 */

					/* node '/soc/peripheral@50000000/power@10e000/gpregret1@500/boot_mode@0' defined in zephyr\boards\nordic\nrf54l15dk\nrf54l_05_10_15_cpuapp_common.dtsi:107 */
					boot_mode0: boot_mode@0 {
						compatible = "zephyr,retention"; /* in zephyr\boards\nordic\nrf54l15dk\nrf54l_05_10_15_cpuapp_common.dtsi:108 */
						status = "okay";                 /* in zephyr\boards\nordic\nrf54l15dk\nrf54l_05_10_15_cpuapp_common.dtsi:109 */
						reg = < 0x0 0x1 >;               /* in zephyr\boards\nordic\nrf54l15dk\nrf54l_05_10_15_cpuapp_common.dtsi:110 */
					};
				};

				/* node '/soc/peripheral@50000000/power@10e000/gpregret2@504' defined in zephyr\dts\vendor\nordic\nrf54l_05_10_15.dtsi:660 */
				gpregret2: gpregret2@504 {
					#address-cells = < 0x1 >;           /* in zephyr\dts\vendor\nordic\nrf54l_05_10_15.dtsi:661 */
					#size-cells = < 0x1 >;              /* in zephyr\dts\vendor\nordic\nrf54l_05_10_15.dtsi:662 */
					compatible = "nordic,nrf-gpregret"; /* in zephyr\dts\vendor\nordic\nrf54l_05_10_15.dtsi:663 */
					reg = < 0x504 0x1 >;                /* in zephyr\dts\vendor\nordic\nrf54l_05_10_15.dtsi:664 */
					status = "disabled";                /* in zephyr\dts\vendor\nordic\nrf54l_05_10_15.dtsi:665 */
				};
			};

			/* node '/soc/peripheral@50000000/comparator@106000' defined in zephyr\dts\vendor\nordic\nrf54l_05_10_15.dtsi:669 */
			comp: comparator@106000 {
				compatible = "nordic,nrf-comp"; /* in zephyr\dts\vendor\nordic\nrf54l_05_10_15.dtsi:674 */
				reg = < 0x106000 0x1000 >;      /* in zephyr\dts\vendor\nordic\nrf54l_05_10_15.dtsi:675 */
				status = "disabled";            /* in zephyr\dts\vendor\nordic\nrf54l_05_10_15.dtsi:676 */
				interrupts = < 0x106 0x1 >;     /* in zephyr\dts\vendor\nordic\nrf54l_05_10_15.dtsi:677 */
			};

			/* node '/soc/peripheral@50000000/watchdog@108000' defined in zephyr\dts\vendor\nordic\nrf54l_05_10_15.dtsi:684 */
			wdt30: watchdog@108000 {
				compatible = "nordic,nrf-wdt"; /* in zephyr\dts\vendor\nordic\nrf54l_05_10_15.dtsi:685 */
				reg = < 0x108000 0x620 >;      /* in zephyr\dts\vendor\nordic\nrf54l_05_10_15.dtsi:686 */
				interrupts = < 0x108 0x1 >;    /* in zephyr\dts\vendor\nordic\nrf54l_05_10_15.dtsi:687 */
				status = "disabled";           /* in zephyr\dts\vendor\nordic\nrf54l_05_10_15.dtsi:688 */
			};

			/* node '/soc/peripheral@50000000/watchdog@109000' defined in zephyr\dts\vendor\nordic\nrf54l_05_10_15.dtsi:692 */
			wdt31: watchdog@109000 {
				compatible = "nordic,nrf-wdt"; /* in zephyr\dts\vendor\nordic\nrf54l_05_10_15.dtsi:693 */
				reg = < 0x109000 0x620 >;      /* in zephyr\dts\vendor\nordic\nrf54l_05_10_15.dtsi:694 */
				interrupts = < 0x109 0x1 >;    /* in zephyr\dts\vendor\nordic\nrf54l_05_10_15.dtsi:695 */
				status = "disabled";           /* in zephyr\dts\vendor\nordic\nrf54l_05_10_15.dtsi:696 */
			};

			/* node '/soc/peripheral@50000000/gpio@10a000' defined in zephyr\dts\vendor\nordic\nrf54l_05_10_15.dtsi:699 */
			gpio0: gpio@10a000 {
				compatible = "nordic,nrf-gpio";  /* in zephyr\dts\vendor\nordic\nrf54l_05_10_15.dtsi:700 */
				gpio-controller;                 /* in zephyr\dts\vendor\nordic\nrf54l_05_10_15.dtsi:701 */
				reg = < 0x10a000 0x300 >;        /* in zephyr\dts\vendor\nordic\nrf54l_05_10_15.dtsi:702 */
				#gpio-cells = < 0x2 >;           /* in zephyr\dts\vendor\nordic\nrf54l_05_10_15.dtsi:703 */
				ngpios = < 0x5 >;                /* in zephyr\dts\vendor\nordic\nrf54l_05_10_15.dtsi:704 */
				port = < 0x0 >;                  /* in zephyr\dts\vendor\nordic\nrf54l_05_10_15.dtsi:706 */
				gpiote-instance = < &gpiote30 >; /* in zephyr\dts\vendor\nordic\nrf54l_05_10_15.dtsi:707 */
				status = "okay";                 /* in zephyr\boards\nordic\nrf54l15dk\nrf54l_05_10_15_cpuapp_common.dtsi:69 */
				phandle = < 0x12 >;              /* in zephyr\power_test\boards\nrf54l15dk_nrf54l15_cpuapp.overlay:122 */
			};

			/* node '/soc/peripheral@50000000/gpiote@10c000' defined in zephyr\dts\vendor\nordic\nrf54l_05_10_15.dtsi:710 */
			gpiote30: gpiote@10c000 {
				compatible = "nordic,nrf-gpiote"; /* in zephyr\dts\vendor\nordic\nrf54l_05_10_15.dtsi:711 */
				reg = < 0x10c000 0x1000 >;        /* in zephyr\dts\vendor\nordic\nrf54l_05_10_15.dtsi:712 */
				instance = < 0x1e >;              /* in zephyr\dts\vendor\nordic\nrf54l_05_10_15.dtsi:714 */
				interrupts = < 0x10d 0x1 >;       /* in zephyr\dts\arm\nordic\nrf54l_05_10_15_cpuapp.dtsi:92 */
				status = "okay";                  /* in zephyr\boards\nordic\nrf54l15dk\nrf54l_05_10_15_cpuapp_common.dtsi:85 */
				phandle = < 0x11 >;               /* in zephyr\dts\vendor\nordic\nrf54l_05_10_15.dtsi:707 */
			};

			/* node '/soc/peripheral@50000000/regulator@120000' defined in zephyr\dts\vendor\nordic\nrf54l_05_10_15.dtsi:717 */
			regulators: regulator@120000 {
				compatible = "nordic,nrf54l-regulators"; /* in zephyr\dts\vendor\nordic\nrf54l_05_10_15.dtsi:718 */
				reg = < 0x120000 0x1000 >;               /* in zephyr\dts\vendor\nordic\nrf54l_05_10_15.dtsi:719 */
				#address-cells = < 0x1 >;                /* in zephyr\dts\vendor\nordic\nrf54l_05_10_15.dtsi:721 */
				#size-cells = < 0x1 >;                   /* in zephyr\dts\vendor\nordic\nrf54l_05_10_15.dtsi:722 */
				status = "okay";                         /* in zephyr\boards\nordic\nrf54l15dk\nrf54l_05_10_15_cpuapp_common.dtsi:45 */

				/* node '/soc/peripheral@50000000/regulator@120000/regulator@120600' defined in zephyr\dts\vendor\nordic\nrf54l_05_10_15.dtsi:724 */
				vregmain: regulator@120600 {
					compatible = "nordic,nrf5x-regulator"; /* in zephyr\dts\vendor\nordic\nrf54l_05_10_15.dtsi:725 */
					reg = < 0x120600 0x1 >;                /* in zephyr\dts\vendor\nordic\nrf54l_05_10_15.dtsi:726 */
					regulator-name = "VREGMAIN";           /* in zephyr\dts\vendor\nordic\nrf54l_05_10_15.dtsi:728 */
					status = "okay";                       /* in zephyr\power_test\boards\nrf54l15dk_nrf54l15_cpuapp.overlay:79 */
					regulator-initial-mode = < 0x1 >;      /* in zephyr\power_test\boards\nrf54l15dk_nrf54l15_cpuapp.overlay:80 */
				};
			};
		};

		/* node '/soc/rram-controller@5004b000' defined in zephyr\dts\vendor\nordic\nrf54l_05_10_15.dtsi:734 */
		rram_controller: rram-controller@5004b000 {
			compatible = "nordic,rram-controller"; /* in zephyr\dts\vendor\nordic\nrf54l_05_10_15.dtsi:735 */
			reg = < 0x5004b000 0x1000 >;           /* in zephyr\dts\vendor\nordic\nrf54l_05_10_15.dtsi:736 */
			#address-cells = < 0x1 >;              /* in zephyr\dts\vendor\nordic\nrf54l_05_10_15.dtsi:737 */
			#size-cells = < 0x1 >;                 /* in zephyr\dts\vendor\nordic\nrf54l_05_10_15.dtsi:738 */
			interrupts = < 0x4b 0x1 >;             /* in zephyr\dts\vendor\nordic\nrf54l_05_10_15.dtsi:739 */

			/* node '/soc/rram-controller@5004b000/rram@0' defined in zephyr\dts\vendor\nordic\nrf54l_05_10_15.dtsi:741 */
			cpuapp_rram: rram@0 {
				compatible = "soc-nv-flash";   /* in zephyr\dts\vendor\nordic\nrf54l_05_10_15.dtsi:742 */
				erase-block-size = < 0x1000 >; /* in zephyr\dts\vendor\nordic\nrf54l_05_10_15.dtsi:743 */
				write-block-size = < 0x10 >;   /* in zephyr\dts\vendor\nordic\nrf54l_05_10_15.dtsi:744 */
				reg = < 0x0 0x165000 >;        /* in zephyr\dts\vendor\nordic\nrf54l15.dtsi:28 */

				/* node '/soc/rram-controller@5004b000/rram@0/partitions' defined in zephyr\dts\vendor\nordic\nrf54l15_partition.dtsi:8 */
				partitions {
					compatible = "fixed-partitions"; /* in zephyr\dts\vendor\nordic\nrf54l15_partition.dtsi:9 */
					#address-cells = < 0x1 >;        /* in zephyr\dts\vendor\nordic\nrf54l15_partition.dtsi:10 */
					#size-cells = < 0x1 >;           /* in zephyr\dts\vendor\nordic\nrf54l15_partition.dtsi:11 */

					/* node '/soc/rram-controller@5004b000/rram@0/partitions/partition@0' defined in zephyr\dts\vendor\nordic\nrf54l15_partition.dtsi:13 */
					boot_partition: partition@0 {
						label = "mcuboot";     /* in zephyr\dts\vendor\nordic\nrf54l15_partition.dtsi:14 */
						reg = < 0x0 0x10000 >; /* in zephyr\dts\vendor\nordic\nrf54l15_partition.dtsi:15 */
					};

					/* node '/soc/rram-controller@5004b000/rram@0/partitions/partition@10000' defined in zephyr\dts\vendor\nordic\nrf54l15_partition.dtsi:18 */
					slot0_partition: partition@10000 {
						label = "image-0";         /* in zephyr\dts\vendor\nordic\nrf54l15_partition.dtsi:19 */
						reg = < 0x10000 0xa6000 >; /* in zephyr\dts\vendor\nordic\nrf54l15_partition.dtsi:20 */
					};

					/* node '/soc/rram-controller@5004b000/rram@0/partitions/partition@b6000' defined in zephyr\dts\vendor\nordic\nrf54l15_partition.dtsi:23 */
					slot1_partition: partition@b6000 {
						label = "image-1";         /* in zephyr\dts\vendor\nordic\nrf54l15_partition.dtsi:24 */
						reg = < 0xb6000 0xa6000 >; /* in zephyr\dts\vendor\nordic\nrf54l15_partition.dtsi:25 */
					};

					/* node '/soc/rram-controller@5004b000/rram@0/partitions/partition@15c000' defined in zephyr\dts\vendor\nordic\nrf54l15_partition.dtsi:28 */
					storage_partition: partition@15c000 {
						label = "storage";         /* in zephyr\dts\vendor\nordic\nrf54l15_partition.dtsi:29 */
						reg = < 0x15c000 0x9000 >; /* in zephyr\dts\vendor\nordic\nrf54l15_partition.dtsi:30 */
					};
				};
			};
		};

		/* node '/soc/memory@50041000' defined in zephyr\dts\vendor\nordic\nrf54l_05_10_15.dtsi:748 */
		nrf_mpc: memory@50041000 {
			compatible = "nordic,nrf-mpc";     /* in zephyr\dts\vendor\nordic\nrf54l_05_10_15.dtsi:749 */
			reg = < 0x50041000 0x1000 >;       /* in zephyr\dts\vendor\nordic\nrf54l_05_10_15.dtsi:750 */
			#address-cells = < 0x1 >;          /* in zephyr\dts\vendor\nordic\nrf54l_05_10_15.dtsi:751 */
			#size-cells = < 0x1 >;             /* in zephyr\dts\vendor\nordic\nrf54l_05_10_15.dtsi:752 */
			override-num = < 0x5 >;            /* in zephyr\dts\vendor\nordic\nrf54l_05_10_15.dtsi:753 */
			override-granularity = < 0x1000 >; /* in zephyr\dts\vendor\nordic\nrf54l_05_10_15.dtsi:754 */
		};

		/* node '/soc/cpuapp-ppb-bus' defined in zephyr\dts\vendor\nordic\nrf54l_05_10_15.dtsi:757 */
		cpuapp_ppb: cpuapp-ppb-bus {
			#address-cells = < 0x1 >;  /* in zephyr\dts\vendor\nordic\nrf54l_05_10_15.dtsi:758 */
			#size-cells = < 0x1 >;     /* in zephyr\dts\vendor\nordic\nrf54l_05_10_15.dtsi:759 */
			compatible = "simple-bus"; /* in zephyr\dts\arm\nordic\nrf54l_05_10_15_cpuapp.dtsi:67 */
			ranges;                    /* in zephyr\dts\arm\nordic\nrf54l_05_10_15_cpuapp.dtsi:68 */

			/* node '/soc/cpuapp-ppb-bus/interrupt-controller@e000e100' defined in zephyr\dts\vendor\nordic\nrf54l_05_10_15.dtsi:761 */
			cpuapp_nvic: nvic: interrupt-controller@e000e100 {
				#address-cells = < 0x1 >;            /* in zephyr\dts\vendor\nordic\nrf54l_05_10_15.dtsi:762 */
				compatible = "arm,v8m-nvic";         /* in zephyr\dts\vendor\nordic\nrf54l_05_10_15.dtsi:763 */
				reg = < 0xe000e100 0xc00 >;          /* in zephyr\dts\vendor\nordic\nrf54l_05_10_15.dtsi:764 */
				arm,num-irq-priority-bits = < 0x3 >; /* in zephyr\dts\vendor\nordic\nrf54l_05_10_15.dtsi:765 */
				interrupt-controller;                /* in zephyr\dts\vendor\nordic\nrf54l_05_10_15.dtsi:766 */
				#interrupt-cells = < 0x2 >;          /* in zephyr\dts\vendor\nordic\nrf54l_05_10_15.dtsi:767 */
				phandle = < 0x2 >;                   /* in zephyr\dts\arm\nordic\nrf54l_05_10_15_cpuapp.dtsi:26 */
			};

			/* node '/soc/cpuapp-ppb-bus/timer@e000e010' defined in zephyr\dts\vendor\nordic\nrf54l_05_10_15.dtsi:770 */
			cpuapp_systick: systick: timer@e000e010 {
				compatible = "arm,armv8m-systick"; /* in zephyr\dts\vendor\nordic\nrf54l_05_10_15.dtsi:771 */
				reg = < 0xe000e010 0x10 >;         /* in zephyr\dts\vendor\nordic\nrf54l_05_10_15.dtsi:772 */
				status = "disabled";               /* in zephyr\dts\vendor\nordic\nrf54l_05_10_15.dtsi:773 */
			};
		};
	};

	/* node '/chosen' defined in zephyr\dts\arm\nordic\nrf54l_05_10_15_cpuapp.dtsi:19 */
	chosen {
		zephyr,bt-hci = &bt_hci_controller;         /* in zephyr\dts\arm\nordic\nrf54l_05_10_15_cpuapp.dtsi:20 */
		zephyr,entropy = &rng;                      /* in zephyr\dts\arm\nordic\nrf54l_05_10_15_cpuapp.dtsi:21 */
		zephyr,console = &uart20;                   /* in zephyr\boards\nordic\nrf54l15dk\nrf54l_05_10_15_cpuapp_common.dtsi:13 */
		zephyr,shell-uart = &uart20;                /* in zephyr\boards\nordic\nrf54l15dk\nrf54l_05_10_15_cpuapp_common.dtsi:14 */
		zephyr,uart-mcumgr = &uart20;               /* in zephyr\boards\nordic\nrf54l15dk\nrf54l_05_10_15_cpuapp_common.dtsi:15 */
		zephyr,bt-mon-uart = &uart20;               /* in zephyr\boards\nordic\nrf54l15dk\nrf54l_05_10_15_cpuapp_common.dtsi:16 */
		zephyr,bt-c2h-uart = &uart20;               /* in zephyr\boards\nordic\nrf54l15dk\nrf54l_05_10_15_cpuapp_common.dtsi:17 */
		zephyr,flash-controller = &rram_controller; /* in zephyr\boards\nordic\nrf54l15dk\nrf54l_05_10_15_cpuapp_common.dtsi:18 */
		zephyr,flash = &cpuapp_rram;                /* in zephyr\boards\nordic\nrf54l15dk\nrf54l_05_10_15_cpuapp_common.dtsi:19 */
		zephyr,ieee802154 = &ieee802154;            /* in zephyr\boards\nordic\nrf54l15dk\nrf54l_05_10_15_cpuapp_common.dtsi:20 */
		zephyr,boot-mode = &boot_mode0;             /* in zephyr\boards\nordic\nrf54l15dk\nrf54l_05_10_15_cpuapp_common.dtsi:21 */
		zephyr,code-partition = &slot0_partition;   /* in zephyr\boards\nordic\nrf54l15dk\nrf54l15dk_nrf54l15_cpuapp.dts:17 */
		zephyr,sram = &cpuapp_sram;                 /* in zephyr\boards\nordic\nrf54l15dk\nrf54l15dk_nrf54l15_cpuapp.dts:18 */
	};

	/* node '/rng' defined in zephyr\dts\arm\nordic\nrf54l_05_10_15_cpuapp.dtsi:30 */
	rng: rng {
		status = "okay";                          /* in zephyr\dts\arm\nordic\nrf54l_05_10_15_cpuapp.dtsi:31 */
		compatible = "nordic,nrf-cracen-ctrdrbg"; /* in zephyr\dts\arm\nordic\nrf54l_05_10_15_cpuapp.dtsi:32 */
	};

	/* node '/psa-rng' defined in zephyr\dts\arm\nordic\nrf54l_05_10_15_cpuapp.dtsi:35 */
	psa_rng: psa-rng {
		compatible = "zephyr,psa-crypto-rng"; /* in zephyr\dts\arm\nordic\nrf54l_05_10_15_cpuapp.dtsi:36 */
		status = "disabled";                  /* in zephyr\dts\arm\nordic\nrf54l_05_10_15_cpuapp.dtsi:37 */
	};

	/* node '/leds' defined in zephyr\boards\nordic\nrf54l15dk\nrf54l15dk_common.dtsi:10 */
	leds {
		compatible = "gpio-leds"; /* in zephyr\power_test\boards\nrf54l15dk_nrf54l15_cpuapp.overlay:171 */

		/* node '/leds/led_0' defined in zephyr\boards\nordic\nrf54l15dk\nrf54l15dk_common.dtsi:13 */
		led0: led_0 {
			label = "Green LED 0";      /* in zephyr\boards\nordic\nrf54l15dk\nrf54l15dk_common.dtsi:15 */
			gpios = < &gpio0 0x3 0x0 >; /* in zephyr\power_test\boards\nrf54l15dk_nrf54l15_cpuapp.overlay:122 */
		};

		/* node '/leds/led_1' defined in zephyr\boards\nordic\nrf54l15dk\nrf54l15dk_common.dtsi:18 */
		led1: led_1 {
			label = "Green LED 1";      /* in zephyr\boards\nordic\nrf54l15dk\nrf54l15dk_common.dtsi:20 */
			gpios = < &gpio0 0x4 0x0 >; /* in zephyr\power_test\boards\nrf54l15dk_nrf54l15_cpuapp.overlay:130 */
		};

		/* node '/leds/my_de' defined in zephyr\power_test\boards\nrf54l15dk_nrf54l15_cpuapp.overlay:173 */
		my_de: my_de {
			gpios = < &gpio0 0x4 0x0 >; /* in zephyr\power_test\boards\nrf54l15dk_nrf54l15_cpuapp.overlay:174 */
		};

		/* node '/leds/my_nre' defined in zephyr\power_test\boards\nrf54l15dk_nrf54l15_cpuapp.overlay:177 */
		my_nre: my_nre {
			gpios = < &gpio0 0x5 0x0 >; /* in zephyr\power_test\boards\nrf54l15dk_nrf54l15_cpuapp.overlay:178 */
		};

		/* node '/leds/my_led' defined in zephyr\power_test\boards\nrf54l15dk_nrf54l15_cpuapp.overlay:181 */
		my_led: my_led {
			gpios = < &gpio0 0x3 0x0 >; /* in zephyr\power_test\boards\nrf54l15dk_nrf54l15_cpuapp.overlay:182 */
		};
	};

	/* node '/pwmleds' defined in zephyr\boards\nordic\nrf54l15dk\nrf54l15dk_common.dtsi:34 */
	pwmleds {
		compatible = "pwm-leds"; /* in zephyr\boards\nordic\nrf54l15dk\nrf54l15dk_common.dtsi:35 */

		/* node '/pwmleds/pwm_led_1' defined in zephyr\boards\nordic\nrf54l15dk\nrf54l15dk_common.dtsi:43 */
		pwm_led1: pwm_led_1 {
			pwms = < &pwm20 0x0 0x1312d00 0x0 >; /* in zephyr\boards\nordic\nrf54l15dk\nrf54l15dk_common.dtsi:44 */
		};
	};

	/* node '/buttons' defined in zephyr\boards\nordic\nrf54l15dk\nrf54l15dk_common.dtsi:48 */
	buttons {
		compatible = "gpio-keys"; /* in zephyr\boards\nordic\nrf54l15dk\nrf54l15dk_common.dtsi:49 */

		/* node '/buttons/button_0' defined in zephyr\boards\nordic\nrf54l15dk\nrf54l15dk_common.dtsi:51 */
		button0: button_0 {
			label = "Push button 0";     /* in zephyr\boards\nordic\nrf54l15dk\nrf54l15dk_common.dtsi:53 */
			zephyr,code = < 0xb >;       /* in zephyr\boards\nordic\nrf54l15dk\nrf54l15dk_common.dtsi:54 */
			gpios = < &gpio1 0x5 0x11 >; /* in zephyr\power_test\boards\nrf54l15dk_nrf54l15_cpuapp.overlay:126 */
		};

		/* node '/buttons/button_1' defined in zephyr\boards\nordic\nrf54l15dk\nrf54l15dk_common.dtsi:57 */
		button1: button_1 {
			label = "Push button 1";     /* in zephyr\boards\nordic\nrf54l15dk\nrf54l15dk_common.dtsi:59 */
			zephyr,code = < 0x2 >;       /* in zephyr\boards\nordic\nrf54l15dk\nrf54l15dk_common.dtsi:60 */
			gpios = < &gpio1 0x6 0x11 >; /* in zephyr\power_test\boards\nrf54l15dk_nrf54l15_cpuapp.overlay:118 */
		};

		/* node '/buttons/button_2' defined in zephyr\boards\nordic\nrf54l15dk\nrf54l15dk_common.dtsi:63 */
		button2: button_2 {
			label = "Push button 2";     /* in zephyr\boards\nordic\nrf54l15dk\nrf54l15dk_common.dtsi:65 */
			zephyr,code = < 0x3 >;       /* in zephyr\boards\nordic\nrf54l15dk\nrf54l15dk_common.dtsi:66 */
			gpios = < &gpio1 0x7 0x11 >; /* in zephyr\power_test\boards\nrf54l15dk_nrf54l15_cpuapp.overlay:114 */
		};
	};

	/* node '/aliases' defined in zephyr\boards\nordic\nrf54l15dk\nrf54l15dk_common.dtsi:76 */
	aliases {
		led0 = &led0;                      /* in zephyr\boards\nordic\nrf54l15dk\nrf54l15dk_common.dtsi:77 */
		led1 = &led1;                      /* in zephyr\boards\nordic\nrf54l15dk\nrf54l15dk_common.dtsi:78 */
		pwm-led0 = &pwm_led1;              /* in zephyr\boards\nordic\nrf54l15dk\nrf54l15dk_common.dtsi:81 */
		sw0 = &button0;                    /* in zephyr\boards\nordic\nrf54l15dk\nrf54l15dk_common.dtsi:82 */
		sw1 = &button1;                    /* in zephyr\boards\nordic\nrf54l15dk\nrf54l15dk_common.dtsi:83 */
		sw2 = &button2;                    /* in zephyr\boards\nordic\nrf54l15dk\nrf54l15dk_common.dtsi:84 */
		watchdog0 = &wdt31;                /* in zephyr\boards\nordic\nrf54l15dk\nrf54l15dk_common.dtsi:86 */
		mcuboot-button0 = &button0;        /* in zephyr\boards\nordic\nrf54l15dk\nrf54l_05_10_15_cpuapp_common.dtsi:25 */
		mcuboot-led0 = &led0;              /* in zephyr\boards\nordic\nrf54l15dk\nrf54l_05_10_15_cpuapp_common.dtsi:26 */
		retainedmemdevice = &retainedmem0; /* in zephyr\power_test\boards\nrf54l15dk_nrf54l15_cpuapp.overlay:97 */
		die-temp0 = &temp;                 /* in zephyr\power_test\boards\nrf54l15dk_nrf54l15_cpuapp.overlay:98 */
		de = &my_de;                       /* in zephyr\power_test\boards\nrf54l15dk_nrf54l15_cpuapp.overlay:165 */
		nre = &my_nre;                     /* in zephyr\power_test\boards\nrf54l15dk_nrf54l15_cpuapp.overlay:166 */
		user-led = &my_led;                /* in zephyr\power_test\boards\nrf54l15dk_nrf54l15_cpuapp.overlay:167 */
	};

	/* node '/cpuapp_sram@2002e000' defined in zephyr\power_test\boards\nrf54l15dk_nrf54l15_cpuapp.overlay:84 */
	cpuapp_sram@2002e000 {
		compatible = "zephyr,memory-region",
		             "mmio-sram";             /* in zephyr\power_test\boards\nrf54l15dk_nrf54l15_cpuapp.overlay:85 */
		reg = < 0x2002e000 0x1000 >;          /* in zephyr\power_test\boards\nrf54l15dk_nrf54l15_cpuapp.overlay:86 */
		zephyr,memory-region = "RetainedMem"; /* in zephyr\power_test\boards\nrf54l15dk_nrf54l15_cpuapp.overlay:87 */
		status = "okay";                      /* in zephyr\power_test\boards\nrf54l15dk_nrf54l15_cpuapp.overlay:88 */

		/* node '/cpuapp_sram@2002e000/retainedmem' defined in zephyr\power_test\boards\nrf54l15dk_nrf54l15_cpuapp.overlay:90 */
		retainedmem0: retainedmem {
			compatible = "zephyr,retained-ram"; /* in zephyr\power_test\boards\nrf54l15dk_nrf54l15_cpuapp.overlay:91 */
			status = "okay";                    /* in zephyr\power_test\boards\nrf54l15dk_nrf54l15_cpuapp.overlay:92 */
		};
	};
};
